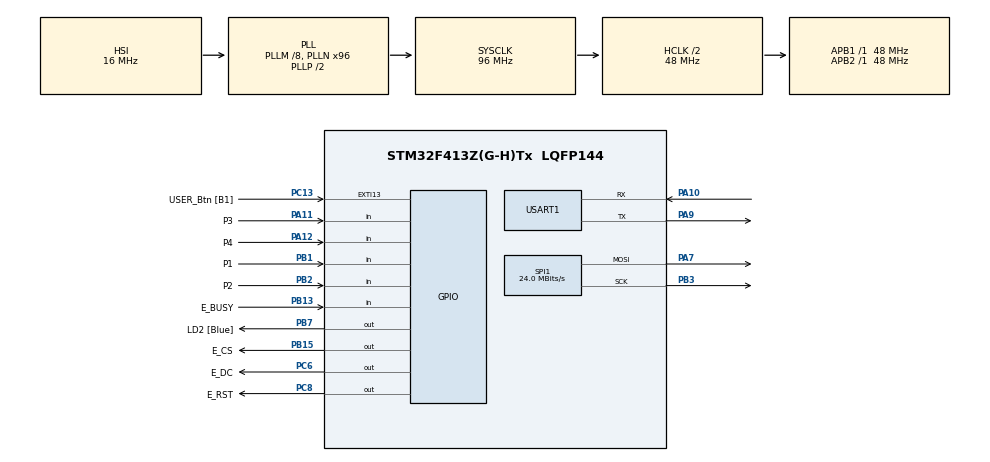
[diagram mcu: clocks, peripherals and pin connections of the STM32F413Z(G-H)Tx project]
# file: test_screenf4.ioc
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Mcu.Family=STM32F4
Mcu.Name=STM32F413Z(G-H)Tx
Mcu.Package=LQFP144
NVIC.PriorityGroup=NVIC_PRIORITYGROUP_4
PA10.Mode=Asynchronous
PA10.Signal=USART1_RX
PA11.GPIO_Label=P3
PA11.GPIO_PuPd=GPIO_PULLUP
PA11.Signal=GPIO_Input
PA12.GPIO_Label=P4
PA12.GPIO_PuPd=GPIO_PULLUP
PA12.Signal=GPIO_Input
PA13.Mode=Serial_Wire
PA13.Signal=SYS_JTMS-SWDIO
PA14.Mode=Serial_Wire
PA14.Signal=SYS_JTCK-SWCLK
PA7.Mode=TX_Only_Simplex_Unidirect_Master
PA7.Signal=SPI1_MOSI
PA9.Mode=Asynchronous
PA9.Signal=USART1_TX
PB1.GPIO_Label=P1
PB1.GPIO_PuPd=GPIO_PULLUP
PB1.Signal=GPIO_Input
PB13.GPIO_Label=E_BUSY
PB13.GPIO_PuPd=GPIO_PULLUP
PB13.Signal=GPIO_Input
PB15.GPIO_Label=E_CS
PB15.Signal=GPIO_Output
PB2.GPIO_Label=P2
PB2.GPIO_PuPd=GPIO_PULLUP
PB2.Signal=GPIO_Input
PB3.Mode=TX_Only_Simplex_Unidirect_Master
PB3.Signal=SPI1_SCK
PB7.GPIO_Label=LD2 [Blue]
PB7.Signal=GPIO_Output
PC13.GPIO_Label=USER_Btn [B1]
PC13.Signal=GPXTI13
PC14-OSC32_IN.Mode=LSE-External-Oscillator
PC14-OSC32_IN.Signal=RCC_OSC32_IN
PC15-OSC32_OUT.Mode=LSE-External-Oscillator
PC15-OSC32_OUT.Signal=RCC_OSC32_OUT
PC6.GPIO_Label=E_DC
PC6.Signal=GPIO_Output
PC8.GPIO_Label=E_RST
PC8.Signal=GPIO_Output
PH0\ -\ OSC_IN.Mode=HSE-External-Oscillator
PH0\ -\ OSC_IN.Signal=RCC_OSC_IN
PH1\ -\ OSC_OUT.Mode=HSE-External-Oscillator
PH1\ -\ OSC_OUT.Signal=RCC_OSC_OUT
ProjectManager.HeapSize=0x2000
ProjectManager.StackSize=0x400
ProjectManager.TargetToolchain=STM32CubeIDE
RCC.48MHZClocksFreq_Value=24000000
RCC.AHBCLKDivider=RCC_SYSCLK_DIV2
RCC.AHBFreq_Value=48000000
RCC.APB1Freq_Value=48000000
RCC.APB1TimFreq_Value=48000000
RCC.APB2Freq_Value=48000000
RCC.APB2TimFreq_Value=48000000
RCC.CortexFreq_Value=48000000
RCC.HCLKFreq_Value=48000000
RCC.HSE_VALUE=8000000
RCC.HSI_VALUE=16000000
RCC.PLLM=8
RCC.PLLMUL=RCC_PLL_MUL9
RCC.PLLN=96
RCC.PLLQ=8
RCC.PRESCALERUSB=RCC_USBCLKSOURCE_PLL_DIV1_5
RCC.SYSCLKFreq_VALUE=96000000
RCC.SYSCLKSource=RCC_SYSCLKSOURCE_PLLCLK
RCC.SYSCLKSourceVirtual=RCC_SYSCLKSOURCE_PLLCLK
RCC.USBFreq_Value=24000000
RCC.VCOOutputFreq_Value=192000000
SPI1.BaudRatePrescaler=SPI_BAUDRATEPRESCALER_2
SPI1.CalculateBaudRate=24.0 MBits/s
SPI1.Direction=SPI_DIRECTION_2LINES
SPI1.Mode=SPI_MODE_MASTER
SPI1.VirtualType=VM_MASTER
USART1.VirtualMode=VM_ASYNC
board=NUCLEO-F413ZH

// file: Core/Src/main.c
/* USER CODE BEGIN Header */
/**
  ******************************************************************************
  * @file           : main.c
  * @brief          : Main program body
  ******************************************************************************
  * @attention
  *
  * <h2><center>&copy; Copyright (c) 2020 STMicroelectronics.
  * All rights reserved.</center></h2>
  *
  * This software component is licensed by ST under BSD 3-Clause license,
  * the "License"; You may not use this file except in compliance with the
  * License. You may obtain a copy of the License at:
  *                        opensource.org/licenses/BSD-3-Clause
  *
  ******************************************************************************
  */
/* USER CODE END Header */

#include "main.h"
#include "epd2in7.h"
#include "epdif.h"
#include "epdpaint.h"
#include "imagedata.h"
//#include "tupian.h"
#include <stdlib.h>
#include <stdio.h>
/* USER CODE BEGIN Includes */
const unsigned char qie[] = {
		1,1,1,1,1,1,1,1,1,1,1,1,1,1,1,1,1,1,1,1,1,1,1,1,1,1,1,1,1,1,1,1,1,1,1,1,1,1,1,1,1,1,1,1,1,1,1,1,1,1,1,1,1,1,1,1,1,1,1,1,1,1,1,1,1,1,1,1,1,1,1,1,1,1,1,1,1,1,1,1,1,1,1,1,1,1,1,1,1,1,1,1,1,1,1,1,1,1,1,1,1,1,1,1,1,1,1,1,1,1,1,1,1,1,1,1,1,1,1,1,1,1,1,1,1,1,1,1,
		1,1,1,1,1,1,1,1,1,1,1,1,1,1,1,1,1,1,1,1,1,1,1,1,1,1,1,1,1,1,1,1,1,1,1,1,1,1,1,1,1,1,1,1,1,1,1,1,1,1,1,1,1,1,1,1,1,1,1,1,1,1,1,1,1,1,1,1,1,1,1,1,1,1,1,1,1,1,1,1,1,1,1,1,1,1,1,1,1,1,1,1,1,1,1,1,1,1,1,1,1,1,1,1,1,1,1,1,1,1,1,1,1,1,1,1,1,1,1,1,1,1,1,1,1,1,1,1,
		1,1,1,1,1,1,1,1,1,1,1,1,1,1,1,1,1,1,1,1,1,1,1,1,1,1,1,1,1,1,1,1,1,1,1,1,1,1,1,1,1,1,1,1,1,1,1,1,1,1,1,1,1,1,1,1,1,1,1,1,1,1,1,1,1,1,1,1,1,1,1,1,1,1,1,1,1,1,1,1,1,1,1,1,1,1,1,1,1,1,1,1,1,1,1,1,1,1,1,1,1,1,1,1,1,1,1,1,1,1,1,1,1,1,1,1,1,1,1,1,1,1,1,1,1,1,1,1,
		1,1,1,1,1,1,1,1,1,1,1,1,1,1,1,1,1,1,1,1,1,1,1,0,0,0,0,0,0,0,0,0,0,0,0,0,0,0,0,0,0,0,1,1,0,0,1,1,1,1,1,1,1,1,1,1,1,1,1,1,1,1,1,1,1,1,1,1,1,1,1,1,1,1,1,1,1,1,1,1,1,1,1,1,1,1,1,1,1,1,1,1,1,1,1,1,1,1,1,1,1,1,1,1,1,1,1,1,1,1,1,1,1,1,1,1,1,1,1,1,1,1,1,1,1,1,1,1,
		1,1,1,1,1,1,1,1,1,1,1,1,1,1,1,1,1,1,1,1,1,1,1,1,1,1,1,1,1,1,1,1,1,1,1,1,1,1,1,1,1,1,1,1,0,0,1,1,1,1,1,1,1,1,1,1,1,1,1,1,1,1,1,1,1,1,1,1,1,0,0,0,0,0,0,0,0,0,0,0,0,0,0,0,0,0,0,0,0,0,0,0,0,0,0,0,0,0,0,0,0,0,0,0,0,0,0,0,0,1,1,1,1,1,1,1,1,1,1,1,1,1,1,1,1,1,1,1,
		1,1,1,1,1,1,1,1,1,1,1,1,1,1,1,1,1,1,1,1,1,1,1,1,1,1,1,1,1,1,1,1,1,1,1,1,1,1,1,1,1,1,1,1,1,1,1,1,1,1,1,1,1,1,1,1,1,1,1,1,1,1,1,1,1,1,1,1,1,1,1,1,1,1,1,1,1,1,1,1,1,1,1,1,1,0,0,1,1,1,1,1,1,1,0,0,0,0,0,0,0,0,0,0,0,0,0,0,0,0,0,0,0,0,0,0,0,0,0,0,0,0,0,0,0,0,0,0,
		1,1,1,1,1,1,1,1,1,1,1,1,1,1,1,1,1,1,1,1,1,1,1,1,1,1,1,1,1,1,1,1,1,1,1,1,1,1,1,1,1,1,1,1,1,1,1,1,1,1,1,1,1,1,1,1,1,1,1,1,1,1,1,1,1,1,1,1,1,1,1,1,1,1,1,1,1,1,1,1,1,1,1,1,1,1,1,1,1,1,1,1,1,1,1,1,1,1,1,1,1,1,1,1,1,1,1,1,1,1,1,1,1,1,1,1,1,1,1,1,1,1,1,1,1,1,1,1,
		1,1,1,1,1,1,1,1,1,1,1,1,1,1,1,1,1,1,1,1,1,1,1,1,1,1,1,1,1,1,1,1,1,1,1,1,1,1,1,1,1,1,1,1,1,1,1,1,1,1,1,1,1,1,1,1,1,1,1,1,1,1,1,1,1,1,1,1,1,1,1,1,1,1,1,1,1,1,1,1,1,1,1,1,1,1,1,1,1,1,1,1,1,1,1,1,1,1,1,1,1,1,1,1,1,1,1,1,1,1,1,1,1,1,1,1,1,1,1,1,1,1,1,1,1,1,1,1,
		1,1,1,1,1,1,1,1,1,1,1,1,1,1,1,1,1,1,1,1,1,1,1,1,1,1,1,1,1,1,1,1,1,1,1,1,1,1,1,1,1,1,1,1,1,1,1,1,1,1,1,1,1,1,1,1,1,1,1,1,1,1,1,1,1,1,1,1,1,1,1,1,1,1,1,1,1,1,1,1,1,1,1,1,1,1,1,1,1,1,1,1,1,1,1,1,1,1,1,1,1,1,1,1,1,1,1,1,1,1,1,1,1,1,1,1,1,1,1,1,1,1,1,1,1,1,1,1,
		1,1,1,1,1,1,1,1,1,1,1,1,1,1,1,0,0,0,0,0,0,0,0,0,0,0,0,0,0,0,0,0,0,0,0,0,0,0,0,1,1,1,1,1,1,1,1,1,1,1,1,1,1,1,1,1,1,1,1,1,1,1,1,1,1,1,1,1,1,1,1,1,1,1,1,1,1,1,1,1,1,1,1,1,1,1,1,1,1,1,1,1,1,1,1,1,1,1,1,1,1,1,1,1,1,1,1,1,1,1,1,1,1,1,1,1,1,1,1,1,1,1,1,1,1,1,1,1,
		1,1,1,1,1,1,1,1,1,1,1,1,1,1,1,1,1,1,1,1,1,1,1,1,1,1,1,1,1,1,1,1,0,0,0,0,0,0,1,0,0,0,0,1,1,1,1,1,1,1,1,1,1,1,1,1,1,1,1,1,1,1,1,1,1,1,1,1,1,1,1,1,1,1,1,1,1,1,1,1,1,1,1,1,1,1,1,1,1,1,0,0,0,0,0,0,0,0,0,0,0,0,1,1,1,1,1,1,1,1,1,1,1,1,1,1,1,1,1,1,1,1,1,1,1,1,1,1,
		1,1,1,1,1,1,1,1,1,1,1,1,1,0,1,1,1,1,1,1,1,1,1,1,1,1,1,1,1,1,1,1,1,1,1,1,1,1,1,1,1,1,1,1,1,1,1,1,1,1,1,1,1,1,1,1,1,1,1,1,1,1,1,1,1,1,1,1,1,1,1,1,1,1,1,1,1,1,1,1,1,1,1,1,1,1,1,1,1,1,0,0,0,0,0,0,0,0,0,0,0,0,0,0,0,0,0,0,0,0,0,0,0,0,0,0,0,0,0,0,0,0,0,0,0,0,0,0,
		1,1,1,1,1,1,1,1,1,1,1,1,0,0,0,0,0,0,0,0,0,0,0,0,0,1,1,1,1,1,1,1,1,1,1,1,1,1,1,1,1,1,1,1,1,1,1,1,1,1,1,1,1,1,1,1,1,1,1,1,1,1,1,1,1,1,1,1,1,1,1,1,1,1,1,1,1,1,1,1,1,1,1,1,1,1,1,1,1,1,1,1,1,1,1,1,1,1,1,1,1,1,1,1,1,1,1,1,1,0,0,0,0,0,0,0,0,0,0,0,0,0,0,0,0,0,0,0,
		1,1,1,1,1,1,1,1,1,1,1,1,1,0,0,0,0,0,0,0,0,0,0,0,0,0,0,0,0,0,0,0,0,0,0,0,0,1,1,1,1,1,1,1,1,1,1,1,1,1,1,1,1,1,1,1,1,1,1,1,1,1,1,1,1,1,1,1,1,1,1,1,1,1,1,1,1,1,1,1,1,1,1,1,1,1,1,1,1,1,1,1,1,1,1,1,1,1,1,1,1,1,1,1,1,1,1,1,1,1,1,1,1,1,1,1,1,1,1,1,1,1,1,1,1,1,1,1,
		1,1,1,1,1,1,1,1,1,1,1,1,1,1,1,1,1,1,1,1,1,1,1,1,1,1,1,1,1,1,1,1,1,1,1,1,1,1,1,1,1,1,1,1,1,1,1,1,1,1,1,1,1,1,1,1,1,1,1,1,1,1,1,1,1,1,1,1,1,1,1,1,1,1,1,1,1,1,1,1,1,1,1,1,1,1,1,1,1,1,1,1,0,0,0,0,0,0,0,0,0,0,0,0,0,0,0,0,0,0,0,0,0,0,0,0,0,0,0,0,0,0,0,0,0,0,0,0,
		1,1,1,1,1,1,1,1,1,1,1,1,1,1,1,1,1,1,1,1,1,1,1,1,1,1,1,1,1,1,1,1,1,1,1,1,1,1,1,1,1,1,1,1,1,1,1,1,1,1,1,1,1,1,1,1,1,1,1,1,1,1,1,1,1,1,1,1,1,1,1,1,1,1,1,1,1,1,1,1,1,1,1,1,1,1,1,1,1,1,1,1,1,1,1,1,0,0,0,0,0,0,0,0,0,0,0,0,0,0,0,0,0,0,0,0,0,0,0,0,0,0,0,0,0,0,0,0,
		1,1,1,1,1,1,1,1,1,1,1,1,1,1,1,1,1,1,1,1,1,1,1,1,1,1,1,1,1,1,1,1,1,1,1,1,1,1,1,1,1,1,1,1,1,1,1,1,1,1,1,1,1,1,1,1,1,1,1,1,1,1,1,1,1,1,1,1,1,1,1,1,1,1,1,1,1,1,1,1,1,1,1,1,1,1,1,1,1,1,1,1,1,1,1,1,1,1,1,1,1,1,1,1,1,1,1,1,1,1,1,1,1,1,1,1,1,1,1,1,1,1,1,1,1,1,1,1,
		1,1,1,1,1,1,1,1,1,1,1,1,1,1,1,1,1,1,1,1,1,1,1,1,1,1,1,1,1,1,1,1,1,1,1,1,1,1,1,1,1,1,1,1,1,1,1,1,1,1,1,1,1,1,1,1,1,1,1,1,1,1,1,1,1,1,1,1,1,1,1,1,1,1,1,1,1,1,1,1,1,1,1,1,1,1,1,1,1,1,1,1,1,1,1,1,1,1,1,1,1,1,1,1,1,1,1,1,1,1,1,1,1,1,1,1,1,1,1,1,1,1,1,1,1,1,1,1,
		1,1,1,1,1,1,1,1,1,1,1,1,1,1,1,1,1,1,1,1,1,1,1,1,1,1,1,1,1,1,1,1,1,1,1,1,1,1,1,1,1,1,1,1,1,1,1,1,1,1,1,1,1,1,1,1,1,1,1,1,1,1,1,1,1,1,1,1,1,1,1,1,1,1,1,1,1,1,1,1,1,1,1,1,1,1,1,1,1,1,1,1,1,1,1,1,1,1,1,1,1,1,1,1,1,1,1,1,1,1,1,1,1,1,1,1,1,1,1,1,1,1,1,1,1,1,1,1,
		1,1,1,1,1,1,1,1,1,1,1,1,1,1,1,1,1,1,1,1,1,1,1,1,1,1,1,1,1,1,1,1,1,1,1,1,1,1,1,1,1,1,1,1,1,1,1,1,1,1,1,1,1,1,1,1,1,1,1,1,1,1,1,1,1,1,1,1,1,1,1,1,1,1,1,1,1,1,1,1,1,1,1,1,1,1,1,1,1,1,1,1,1,1,1,1,1,1,1,1,1,1,1,1,1,1,1,1,1,1,1,1,1,1,1,1,1,1,1,1,1,1,1,1,1,1,1,1,
		1,1,1,1,1,1,1,1,1,1,1,1,1,1,1,1,1,1,1,1,1,1,1,1,1,1,1,1,1,1,1,1,1,1,1,1,1,1,1,1,1,1,1,1,1,1,1,1,1,1,1,1,1,1,1,1,1,1,1,1,1,1,1,1,1,1,1,1,1,1,1,1,1,1,1,1,1,1,1,1,1,1,1,1,1,1,1,1,1,1,1,1,1,1,1,1,1,1,1,1,1,1,1,1,1,1,1,1,1,1,1,1,1,1,1,1,1,1,1,1,1,1,1,1,1,1,1,1,
		1,1,1,1,1,1,1,1,1,1,1,1,1,1,1,1,1,1,1,1,1,1,1,1,1,1,1,1,1,1,1,1,1,1,1,1,1,1,1,1,1,1,1,1,1,1,1,1,1,1,1,1,1,1,1,1,1,1,1,1,1,1,1,1,1,1,1,1,1,1,1,1,1,1,1,1,1,1,1,1,1,1,1,1,1,1,1,1,1,1,1,1,1,1,1,1,1,1,1,1,1,1,1,1,1,1,1,1,1,1,1,1,1,1,1,1,1,1,1,1,1,1,1,1,1,1,1,1,
		1,1,1,1,1,1,1,1,1,1,1,1,1,1,1,1,1,1,1,1,1,1,1,1,1,1,1,1,1,1,1,1,1,1,1,1,1,1,1,1,1,1,1,1,1,1,1,1,1,1,1,1,1,1,1,1,1,1,1,1,1,1,1,1,1,1,1,1,1,1,1,1,1,1,1,1,1,1,1,1,1,1,1,1,1,1,1,1,1,1,1,1,1,1,1,1,1,1,1,1,1,1,1,1,1,1,1,1,1,1,1,1,1,1,1,1,1,1,1,1,1,1,1,1,1,1,1,1,
		1,1,1,1,1,1,1,1,1,1,1,1,1,1,1,1,1,1,1,1,1,1,1,1,1,1,1,1,1,1,1,1,1,1,1,1,1,1,1,1,1,1,1,1,1,1,1,1,1,1,1,1,1,1,1,1,1,1,1,1,1,1,1,1,1,1,1,1,1,1,1,1,1,1,1,1,1,1,1,1,1,1,1,1,1,1,1,1,1,1,1,1,1,1,1,1,1,1,1,1,1,1,1,1,1,1,1,1,1,1,1,1,1,1,1,1,1,1,1,1,1,1,1,1,1,1,1,1,
		1,1,1,1,1,1,1,1,1,1,1,1,1,1,1,1,1,1,1,1,1,1,1,1,1,1,1,1,1,1,1,1,1,1,1,1,1,1,1,1,1,1,1,1,1,1,1,1,1,1,1,1,1,1,1,1,1,1,1,1,1,1,1,1,1,1,1,1,1,1,1,1,1,1,1,1,1,1,1,1,1,1,1,1,1,1,1,1,1,1,1,1,1,1,1,1,1,1,1,1,1,1,1,1,1,1,1,1,1,1,1,1,1,1,1,1,1,1,1,1,1,1,1,1,1,1,1,1,
		1,1,1,1,1,1,1,1,1,1,1,1,1,1,1,1,1,1,1,1,1,1,1,1,1,1,1,1,1,1,1,1,1,1,1,1,1,1,1,1,1,1,1,1,1,1,1,1,1,1,1,1,1,1,1,1,1,1,1,1,1,1,1,1,1,1,1,1,1,1,1,1,1,1,1,1,1,1,1,1,1,1,1,1,1,1,1,1,1,1,1,1,1,1,1,1,1,1,1,1,1,1,1,1,1,1,1,1,1,1,1,1,1,1,1,1,1,1,1,1,1,1,1,1,1,1,1,1,
		1,1,1,1,1,1,1,1,1,1,1,1,1,1,1,1,1,1,1,1,1,1,1,1,1,1,1,1,1,1,1,1,1,1,1,1,1,1,1,1,1,1,1,1,1,1,1,1,1,1,1,1,1,1,1,1,1,1,1,1,1,1,1,1,1,1,1,1,1,1,1,1,1,1,1,1,1,1,1,1,1,1,1,1,1,1,1,1,1,1,1,1,1,1,1,1,1,1,1,1,1,1,1,1,1,1,1,1,1,1,1,1,1,1,1,1,1,1,1,1,1,1,1,1,1,1,1,1,
		0,0,0,0,1,0,0,1,1,1,1,1,1,1,1,1,1,1,1,1,1,1,1,1,1,1,1,1,1,1,1,1,1,1,1,1,1,1,1,1,1,1,1,1,1,1,1,1,1,1,1,1,1,1,1,1,1,1,1,1,1,1,1,1,1,1,1,1,1,1,1,1,1,1,1,1,1,1,1,1,1,1,1,1,1,1,1,1,1,1,1,1,1,1,1,1,1,1,1,1,1,1,1,1,1,1,1,1,1,1,1,1,1,1,1,1,1,1,1,1,1,1,1,1,1,1,1,1,
		0,1,1,1,1,1,1,1,1,1,1,1,1,1,1,1,1,1,1,1,1,1,1,1,1,1,1,1,1,1,1,1,1,1,1,1,1,1,1,1,1,1,1,1,1,1,1,1,1,1,1,1,1,1,1,1,1,1,1,1,1,1,1,1,1,1,1,1,1,1,1,1,1,1,1,1,1,1,1,1,1,1,1,1,1,1,1,1,1,1,1,1,1,1,1,1,1,1,1,1,1,1,1,1,1,1,1,1,1,1,1,1,1,1,1,1,1,1,1,1,1,1,1,1,1,1,1,1,
		1,1,1,1,1,1,1,1,1,1,1,1,1,1,1,1,1,1,1,1,1,1,1,1,1,1,1,1,1,1,1,1,1,1,1,1,1,1,1,1,1,1,1,1,1,1,1,1,1,1,1,1,1,1,1,1,1,1,1,1,1,1,1,1,1,1,1,1,1,1,1,1,1,1,1,1,1,1,1,1,1,1,1,1,1,1,1,1,1,1,1,1,1,1,1,1,1,1,1,1,1,1,1,1,1,1,1,1,1,1,1,1,1,1,1,1,1,1,1,1,1,1,1,1,1,1,1,1,
		1,1,1,1,1,1,1,1,1,1,1,1,1,1,1,1,1,1,1,1,1,1,1,1,1,1,1,1,1,1,1,1,1,1,1,1,1,1,1,1,1,1,1,1,1,1,1,1,1,1,1,1,1,1,1,1,1,1,1,1,1,1,1,1,1,1,1,1,1,1,1,1,1,1,1,1,1,1,1,1,1,1,1,1,1,1,1,1,1,1,1,1,1,1,1,1,1,1,1,1,1,1,1,1,1,1,1,1,1,1,1,1,1,1,1,1,1,1,1,1,1,1,1,1,1,1,1,1,
		1,1,1,1,1,1,1,1,1,1,1,1,1,1,1,1,1,1,1,1,1,1,1,1,1,1,1,1,1,1,1,1,1,1,1,1,1,1,1,1,1,1,1,1,1,1,1,1,1,1,1,1,1,1,1,1,1,1,1,1,1,1,1,1,1,1,1,1,1,1,1,1,1,1,1,1,1,1,1,1,1,1,1,1,1,1,1,1,1,1,1,1,1,1,1,1,1,1,1,1,1,1,1,1,1,1,1,1,1,1,1,1,1,1,1,1,1,1,1,1,1,1,1,1,1,1,1,1,
		1,1,1,1,1,1,1,1,1,1,1,1,1,1,1,1,1,1,1,1,1,1,1,1,1,1,1,1,1,1,1,1,1,1,1,1,1,1,1,1,1,1,1,1,1,1,1,1,1,1,1,1,1,1,1,1,1,1,1,1,1,1,1,1,1,1,1,1,1,1,1,1,1,1,1,1,1,1,1,1,1,1,1,1,1,1,1,1,1,1,1,1,1,1,1,1,1,1,1,1,1,1,1,1,1,1,1,1,1,1,1,1,1,1,1,1,1,1,1,1,1,1,1,1,1,1,1,1,
		1,1,1,1,1,1,1,1,1,1,1,1,1,1,1,1,1,1,1,1,1,1,1,1,1,1,1,1,1,1,1,1,1,1,1,1,1,1,1,1,1,1,1,1,1,1,1,1,1,1,1,1,1,1,1,1,1,1,1,1,1,1,1,1,1,1,1,1,1,1,1,1,1,1,1,1,1,1,1,1,1,1,1,1,1,1,1,1,1,1,1,1,1,1,1,1,1,1,1,1,1,1,1,1,1,1,1,1,1,1,1,1,1,1,1,1,1,1,1,1,1,1,1,1,1,1,1,1,
		1,1,1,1,1,1,1,1,1,1,1,1,1,1,1,1,1,1,1,1,1,1,1,1,1,1,1,1,1,1,1,1,1,1,1,1,1,1,1,1,1,1,1,1,1,1,1,1,1,1,1,1,1,1,1,1,1,1,1,1,1,1,1,1,1,1,1,1,1,1,1,1,1,1,1,1,1,1,1,1,1,1,1,1,1,1,1,1,1,1,1,1,1,1,1,1,1,1,1,1,1,1,1,1,1,1,1,1,1,1,1,1,1,1,1,1,1,1,1,1,1,1,1,1,1,1,1,1,
		1,1,1,1,1,1,1,1,1,1,1,1,1,1,1,1,1,1,1,1,1,1,1,1,1,1,1,1,1,1,1,1,1,1,1,1,1,1,1,1,1,1,1,1,1,1,1,1,1,1,1,1,1,1,1,1,1,1,1,1,1,1,1,1,1,1,1,1,1,1,1,1,1,1,1,1,1,1,1,1,1,1,1,1,1,1,1,1,1,1,1,1,1,1,1,1,1,1,1,1,1,1,1,1,1,1,1,1,1,1,1,1,1,1,1,1,1,1,1,1,1,1,1,1,1,1,1,1,
		1,1,1,1,1,1,1,1,1,1,1,1,1,1,1,1,1,1,1,1,1,1,1,1,1,1,1,1,1,1,1,1,1,1,1,1,1,1,1,1,1,1,1,1,1,1,1,1,1,1,1,1,1,1,1,1,1,1,1,1,1,1,1,1,1,1,1,1,1,1,1,1,1,1,1,1,1,1,1,1,1,1,1,1,1,1,1,1,1,1,1,1,1,1,1,1,1,1,1,1,1,1,1,1,1,1,1,1,1,1,1,1,1,1,1,1,1,1,1,1,1,1,1,1,1,1,1,1,
		1,1,1,1,1,1,1,1,1,1,1,1,1,1,1,1,1,1,1,1,1,1,1,1,1,1,1,1,1,1,1,1,1,1,1,1,1,1,1,1,1,1,1,1,1,1,1,1,1,1,1,1,1,1,1,1,1,1,1,1,1,1,1,1,1,1,1,1,1,1,1,1,1,1,1,1,1,1,1,1,1,1,1,1,1,1,1,1,1,1,1,1,1,1,1,1,1,1,1,1,1,1,1,1,1,1,1,1,1,1,1,1,1,1,1,1,1,1,1,1,1,1,1,1,1,1,1,1,
		1,1,1,1,1,1,1,1,1,1,1,1,1,1,1,1,1,1,1,1,1,1,1,1,1,1,1,1,1,1,1,1,1,1,1,1,1,1,1,1,1,1,1,1,1,1,1,1,1,1,1,1,1,1,1,1,1,1,1,1,1,1,1,1,1,1,1,1,1,1,1,1,1,1,1,1,1,1,1,1,1,1,1,1,1,1,1,1,1,1,1,1,1,1,1,1,1,1,1,1,1,1,1,1,1,1,1,1,1,1,1,1,1,1,1,1,1,1,1,1,1,1,1,1,1,1,1,1,
		1,1,1,1,1,1,1,1,1,1,1,1,1,1,1,1,1,1,1,1,1,1,1,1,1,1,1,1,1,1,1,1,1,1,1,1,1,1,1,1,1,1,1,1,1,1,1,1,1,1,1,1,1,1,1,1,1,1,1,1,1,1,1,1,1,1,1,1,1,1,1,1,0,1,1,1,1,1,1,1,1,1,1,1,1,1,1,1,1,1,1,1,1,1,1,1,1,1,1,1,1,1,1,1,1,1,1,1,1,1,1,1,1,1,1,1,1,1,1,1,1,1,1,1,1,1,1,1,
		1,1,1,1,1,1,1,1,1,1,1,1,1,1,1,1,1,1,1,1,1,1,1,1,1,1,1,1,1,1,1,1,1,1,1,1,1,1,1,1,1,1,1,1,1,1,1,1,1,1,1,1,1,1,1,1,1,1,1,1,1,1,1,0,1,1,1,0,0,0,0,0,0,0,0,0,1,1,1,1,1,1,1,1,1,1,1,1,1,1,1,1,1,1,1,1,1,1,1,1,1,1,1,1,1,1,1,1,1,1,1,1,1,1,1,1,1,1,1,1,1,1,1,1,1,1,1,1,
		1,1,1,1,1,1,1,1,1,1,1,1,1,1,1,1,1,1,1,1,1,1,1,1,1,1,1,1,1,1,1,1,1,1,1,1,1,1,1,1,1,1,1,1,1,1,1,1,1,1,1,1,1,1,1,1,1,1,1,1,0,0,0,0,0,0,0,0,0,0,0,0,0,0,0,0,0,0,1,1,1,1,1,1,1,1,1,1,1,1,1,1,1,1,1,1,1,1,1,1,1,1,1,1,1,1,1,1,1,1,1,1,1,1,1,1,1,1,1,1,1,1,1,1,1,1,1,1,
		1,1,1,1,1,1,1,1,1,1,1,1,1,1,1,0,0,0,0,0,0,0,1,1,1,1,1,1,1,1,1,1,1,1,1,1,1,1,1,1,1,1,1,1,1,1,1,1,1,1,1,1,1,1,1,0,0,0,0,0,0,0,0,0,0,0,0,0,0,0,0,0,0,0,0,0,0,0,0,0,1,1,1,1,1,1,1,1,1,1,1,1,1,1,1,1,1,1,1,1,1,1,1,1,1,1,1,1,1,1,1,1,1,1,1,1,1,1,1,1,1,1,1,1,1,1,1,1,
		1,1,1,1,1,1,1,1,1,1,1,1,1,1,0,0,1,1,1,1,1,1,1,1,1,1,1,1,1,1,1,1,1,1,1,1,1,1,1,1,1,1,1,1,1,1,1,1,1,1,0,0,0,0,0,0,0,0,0,0,0,0,0,0,0,0,0,0,0,0,0,0,0,0,0,0,0,0,0,0,0,0,1,1,1,1,1,1,1,1,1,1,1,1,1,1,1,1,1,1,1,1,1,1,1,1,0,0,0,0,0,0,0,0,0,0,0,0,0,0,0,0,0,0,0,0,0,0,
		1,1,1,1,1,1,1,1,1,1,1,1,1,1,0,0,1,1,1,1,1,1,1,1,1,1,1,1,1,1,1,1,1,1,1,1,1,1,1,1,1,1,1,1,1,1,1,1,0,0,0,0,0,0,0,0,0,0,0,0,0,0,0,0,0,0,0,0,0,0,0,0,0,0,0,0,0,0,0,0,0,0,1,1,1,1,1,1,1,1,1,1,1,1,1,1,1,1,1,1,1,1,1,1,1,1,1,1,1,1,1,1,1,1,1,1,1,1,1,1,1,1,1,1,1,1,0,0,
		1,1,1,1,1,1,1,1,1,1,1,1,1,1,1,0,1,1,1,1,1,1,1,1,1,1,1,1,1,1,1,1,1,1,1,1,1,1,1,1,1,1,1,1,1,1,0,0,0,0,0,0,0,0,0,0,0,0,0,0,0,0,0,0,0,0,0,0,0,0,0,0,0,0,0,0,0,0,0,0,0,0,0,1,1,1,1,1,1,1,1,1,1,1,1,1,1,1,1,1,1,1,1,1,1,1,1,1,1,1,1,1,1,1,1,1,1,1,1,1,1,1,1,1,1,1,1,1,
		1,1,1,1,1,1,1,1,1,1,1,1,1,1,1,1,1,1,1,1,1,1,1,1,1,1,1,1,1,1,1,1,1,1,1,1,1,1,1,1,1,1,1,1,0,0,0,0,0,0,0,0,0,0,0,0,0,0,0,0,0,0,0,0,0,0,0,0,0,0,0,0,0,0,0,0,0,0,0,0,0,0,0,1,1,1,1,1,1,1,1,1,1,1,1,1,1,1,1,1,1,1,1,1,1,1,1,1,1,1,1,1,1,1,1,1,1,1,1,1,1,1,1,1,1,1,1,1,
		1,1,1,1,1,1,1,1,1,1,1,1,1,1,1,1,1,1,1,1,1,1,1,1,1,1,1,1,1,1,1,1,1,1,1,1,1,1,1,1,1,1,1,1,0,0,0,0,0,0,0,0,0,0,0,0,0,0,0,0,0,0,0,0,0,0,0,0,0,0,0,0,0,0,0,0,0,0,0,0,0,0,0,0,1,1,1,1,1,1,1,1,1,1,1,1,1,1,1,1,1,1,1,1,1,1,1,1,1,1,1,1,1,1,1,1,1,1,1,1,1,1,1,1,1,1,1,1,
		1,1,1,1,1,1,1,1,1,1,1,1,1,1,1,1,1,1,1,1,1,1,1,1,1,1,1,1,1,1,1,1,1,1,1,1,1,1,1,1,1,1,1,0,0,0,0,0,0,0,0,0,0,0,0,0,0,0,0,0,0,0,0,0,0,0,0,0,0,0,0,0,0,0,0,0,0,0,0,0,0,0,0,0,0,1,1,1,1,1,1,1,1,1,1,1,1,1,1,1,1,1,1,1,1,1,1,1,1,1,1,1,1,1,1,1,1,1,1,1,1,1,1,1,1,1,1,1,
		1,1,1,1,1,1,1,1,1,1,1,1,1,1,1,1,1,1,1,1,1,1,1,1,1,1,1,1,1,1,1,1,1,1,1,1,1,1,1,1,1,1,0,0,0,0,0,0,0,0,0,0,0,0,0,0,0,0,0,0,0,0,0,0,0,0,0,0,0,0,0,0,0,0,0,0,0,0,0,0,0,0,0,0,0,1,1,1,1,1,1,1,1,1,1,1,1,1,1,1,1,1,1,1,1,1,1,1,1,1,1,1,1,1,1,1,1,1,1,1,1,1,1,1,1,1,1,1,
		1,1,1,1,1,1,1,1,1,1,1,1,1,1,1,1,1,1,1,1,1,1,1,1,1,1,1,1,1,1,1,1,1,1,1,1,1,1,1,1,0,0,0,0,0,0,0,0,0,0,0,0,0,0,0,0,0,0,0,0,0,0,0,0,0,0,0,0,0,0,0,0,0,0,0,0,0,0,0,0,0,0,0,0,0,0,1,1,1,1,1,1,1,1,1,1,1,1,1,1,1,1,1,1,1,1,1,1,1,1,1,1,1,1,1,1,1,1,1,1,1,1,1,1,1,1,1,1,
		1,1,1,1,1,1,1,1,1,1,1,1,1,1,1,1,1,1,1,1,1,1,1,1,1,1,1,1,1,1,1,1,1,1,1,1,1,1,1,1,0,0,0,0,0,0,0,0,0,0,0,0,0,0,0,0,0,0,0,0,0,0,0,0,0,0,0,0,0,0,0,0,0,0,0,0,0,0,0,0,0,0,0,0,0,0,0,0,1,1,1,1,1,1,1,1,1,1,1,1,1,1,1,1,1,1,1,1,1,1,1,1,1,1,1,1,1,1,1,1,1,1,1,1,1,1,1,1,
		1,1,1,1,1,1,1,1,1,1,1,1,1,1,1,1,1,1,1,1,1,1,1,1,1,1,1,1,1,1,1,1,1,1,1,1,1,1,1,0,0,0,0,0,0,0,0,0,0,0,0,0,0,0,0,0,0,0,0,0,0,0,0,0,0,0,0,0,0,0,0,0,0,0,0,0,0,0,0,0,0,0,0,0,0,0,0,0,0,0,0,1,1,1,1,1,1,1,1,1,1,1,1,1,1,1,1,1,1,1,1,1,1,1,1,1,1,1,1,1,1,1,1,1,1,1,1,1,
		1,1,1,1,1,1,1,1,1,1,1,1,1,1,1,1,1,1,1,1,1,1,1,1,1,1,1,1,1,1,1,1,1,1,1,1,1,1,0,0,0,0,0,0,0,0,0,0,0,0,0,0,0,0,0,0,0,0,0,0,0,0,0,0,0,0,0,0,0,0,0,0,0,0,0,0,0,0,0,0,0,0,0,0,0,0,0,0,0,0,0,1,1,1,1,1,1,1,1,1,1,1,1,1,1,1,1,1,1,1,1,1,1,1,1,1,1,1,1,1,1,1,1,1,1,1,1,1,
		1,1,1,1,1,1,1,1,1,1,1,1,1,1,1,1,1,1,1,1,1,1,1,1,1,1,1,1,1,1,1,1,1,1,1,1,0,0,0,0,0,0,0,0,0,0,0,0,0,0,0,0,0,0,0,0,0,0,0,0,0,0,0,0,0,0,0,0,0,0,0,0,0,0,0,0,0,0,0,0,0,0,0,0,0,0,0,0,0,0,0,0,0,1,1,1,1,1,1,1,1,1,1,1,1,1,1,1,1,1,1,1,1,1,1,1,1,1,1,1,1,1,1,1,1,1,1,1,
		1,1,1,1,1,1,1,1,1,1,1,1,1,1,1,1,1,1,1,1,1,1,1,1,1,1,1,1,1,1,1,1,1,1,1,1,0,0,0,0,0,0,0,0,0,0,0,0,0,0,0,0,0,0,0,0,0,0,0,0,0,0,0,0,0,0,0,0,0,0,0,0,0,0,0,0,0,0,0,0,0,0,0,0,0,0,0,0,0,0,0,0,0,0,1,1,1,1,1,1,1,1,1,1,1,1,1,1,1,1,1,1,1,1,1,1,1,1,1,1,1,1,1,1,1,1,1,1,
		1,1,1,1,1,1,1,1,1,1,1,1,1,1,1,1,1,1,1,1,1,1,1,1,1,1,1,1,1,1,1,1,1,1,1,0,0,0,0,0,0,0,0,0,0,0,0,0,0,0,0,0,0,0,0,0,0,0,0,0,0,0,0,0,0,0,0,0,0,0,0,0,0,0,0,0,0,0,0,0,0,0,0,0,0,0,0,0,0,0,0,0,0,0,1,1,1,1,1,1,1,1,1,1,1,1,1,1,1,1,1,1,1,1,1,1,1,1,1,1,1,1,1,1,1,1,1,1,
		1,1,1,1,1,1,1,1,1,1,1,1,1,1,1,1,1,1,1,1,1,1,1,1,1,1,1,1,1,1,1,1,1,1,1,0,0,0,0,0,0,0,0,0,0,0,0,0,0,0,0,0,0,0,0,0,0,0,0,0,0,0,0,0,0,0,0,0,0,0,0,0,0,0,0,0,0,0,0,0,0,0,0,0,0,0,0,0,0,0,0,0,0,0,0,1,1,1,1,1,1,1,1,1,1,1,1,1,1,1,1,1,1,1,1,1,1,1,1,1,1,1,1,1,1,1,1,1,
		1,1,1,1,1,1,1,1,1,1,1,1,1,1,1,1,1,1,1,1,1,1,1,1,1,1,1,1,1,1,1,1,1,1,0,0,0,0,0,0,0,0,0,0,0,0,0,0,0,0,0,0,0,0,0,0,0,0,0,0,0,0,0,0,0,0,0,0,0,0,0,0,0,0,0,0,0,0,0,0,0,0,0,0,0,0,0,0,0,0,0,0,0,0,0,0,1,1,1,1,1,1,1,1,1,1,1,1,1,1,1,1,1,1,1,1,1,1,1,1,1,1,1,1,1,1,1,1,
		1,1,1,1,1,1,1,1,1,1,1,1,1,1,1,1,1,1,1,1,1,1,1,1,1,1,1,1,1,1,1,1,1,1,0,0,0,0,0,0,0,0,0,0,0,0,0,0,0,0,0,0,0,0,0,0,0,0,0,0,0,0,0,0,0,0,0,0,0,0,0,0,0,0,0,0,0,0,0,0,0,0,0,0,0,0,0,0,0,0,0,0,0,0,0,0,1,1,1,1,1,1,1,1,1,1,1,1,1,1,1,1,1,1,1,1,1,1,1,1,1,1,1,1,1,1,1,1,
		1,1,1,1,1,1,1,1,1,1,1,1,1,1,1,1,1,1,1,1,1,1,1,1,1,1,1,1,1,1,1,1,1,1,0,0,0,0,0,0,0,0,0,0,0,0,0,0,0,0,0,0,0,0,0,0,0,0,0,0,0,0,0,0,0,0,0,0,0,0,0,0,0,0,0,0,0,0,0,0,0,0,0,0,0,0,0,0,0,0,0,0,0,0,0,0,0,1,1,1,1,1,1,1,1,1,1,1,1,1,1,1,1,1,1,1,1,1,1,1,1,1,1,1,1,1,1,1,
		1,1,1,1,1,1,1,1,1,1,1,1,1,1,1,1,1,1,1,1,1,1,1,1,1,1,1,1,1,1,1,1,1,1,0,0,0,0,0,0,0,0,0,0,0,0,0,0,0,0,0,0,0,0,0,0,0,0,0,0,0,0,0,0,0,0,0,0,0,0,0,0,0,0,0,0,0,0,0,0,0,0,0,0,0,0,0,0,0,0,0,0,0,0,0,0,0,0,1,1,1,1,1,1,1,1,1,1,1,1,1,1,1,1,1,1,1,1,1,1,1,1,1,1,1,1,1,1,
		1,1,1,1,1,1,1,1,1,1,1,1,1,1,1,1,1,1,1,1,1,1,1,1,1,1,1,1,1,1,1,1,1,0,0,0,0,0,0,0,0,0,0,0,0,0,0,0,0,0,0,0,0,0,0,0,0,0,0,0,0,0,0,0,0,0,0,0,0,0,0,0,0,0,0,0,0,0,0,0,0,0,0,0,0,0,0,0,0,0,0,0,0,0,0,0,0,0,1,1,1,1,1,1,1,1,1,1,1,1,1,1,1,1,1,1,1,1,1,1,1,1,1,1,1,1,1,1,
		1,1,1,1,1,1,1,1,1,1,1,1,1,1,1,1,1,1,1,1,1,1,1,1,1,1,1,1,1,1,1,1,1,0,0,0,0,0,0,0,0,0,0,0,0,0,0,0,0,0,0,0,0,0,0,0,0,0,0,0,0,0,0,0,0,0,0,0,0,0,0,0,0,0,0,0,0,1,1,1,0,0,0,0,0,0,0,0,0,0,0,0,0,0,0,0,0,0,1,1,1,1,1,1,1,1,1,1,1,1,1,1,1,1,1,1,1,1,1,1,1,1,1,1,1,1,1,1,
		1,1,1,1,1,1,1,1,1,1,1,1,1,1,1,1,1,1,1,1,1,1,1,1,1,1,1,1,1,1,1,1,1,0,0,0,0,0,0,0,0,0,0,0,0,0,0,0,0,0,0,0,0,0,0,0,0,0,0,0,0,0,0,0,0,0,0,0,0,0,1,1,1,1,1,1,1,1,1,1,1,1,1,0,0,0,0,0,0,0,0,0,0,0,0,0,0,0,1,1,1,1,1,1,1,1,1,1,1,1,1,1,1,1,1,1,1,1,1,1,1,1,1,1,1,1,1,1,
		1,1,1,1,1,1,1,1,1,1,1,1,1,1,1,1,1,1,1,1,1,1,1,1,1,1,1,1,1,1,1,1,1,0,0,0,0,0,0,0,0,0,0,1,1,1,1,1,1,1,1,0,0,0,0,0,0,0,0,0,0,0,0,0,0,0,0,1,1,1,1,1,1,1,1,1,1,1,1,1,1,1,1,1,1,0,0,0,0,0,0,0,0,0,0,0,0,0,0,1,1,1,1,1,1,1,1,1,1,1,1,1,1,1,1,1,1,1,1,1,1,1,1,1,1,1,1,1,
		1,1,1,1,1,1,1,1,1,1,1,1,1,1,1,1,1,1,1,1,1,1,1,1,1,1,1,1,1,1,1,1,0,0,0,0,0,0,0,0,0,1,1,1,1,1,1,1,1,1,1,1,1,1,1,1,1,0,0,0,0,0,0,0,1,1,1,1,1,1,1,1,1,1,1,1,1,1,1,1,1,1,1,1,1,0,0,0,0,0,0,0,0,0,0,0,0,0,0,1,1,1,1,1,1,1,1,1,1,1,1,1,1,1,1,1,1,1,1,1,1,1,1,1,1,1,1,1,
		1,1,1,1,1,1,1,1,1,1,1,1,1,1,1,1,1,1,1,1,1,1,1,1,1,1,1,1,1,1,1,1,0,0,0,0,0,0,0,0,1,1,1,1,1,1,1,1,1,1,1,1,1,1,1,1,1,1,1,0,0,0,0,1,1,1,1,1,1,1,1,1,1,1,1,1,1,1,1,1,1,1,1,1,1,0,0,0,0,0,0,0,0,0,0,0,0,0,0,1,1,1,1,1,1,1,1,1,1,1,1,1,1,1,1,1,1,1,1,1,1,1,1,1,1,1,1,1,
		1,1,1,1,1,1,1,1,1,1,1,1,1,1,1,1,1,1,1,1,1,1,1,1,1,1,1,1,1,1,1,1,0,0,0,0,0,0,0,1,1,1,1,1,1,1,1,1,1,1,1,1,1,1,1,1,1,1,1,1,0,1,1,1,1,1,1,1,1,1,1,1,1,1,1,1,1,1,1,1,1,1,1,1,1,0,0,1,0,0,0,0,0,0,0,0,0,0,0,1,1,1,1,1,1,1,1,1,1,1,1,1,1,1,1,1,1,1,1,1,1,1,1,1,1,1,1,1,
		1,1,1,1,1,1,1,1,1,1,1,1,1,1,1,1,1,1,1,1,1,1,1,1,1,1,1,1,1,1,1,1,0,0,0,0,0,0,1,1,1,1,1,1,1,1,1,1,1,1,1,1,1,1,1,1,1,1,1,1,1,1,1,1,1,1,1,1,1,1,1,1,1,1,1,1,1,1,1,1,1,1,1,1,1,1,1,1,1,0,0,0,0,0,0,0,0,0,0,1,1,1,1,1,1,1,1,1,1,1,1,1,1,1,1,1,1,1,1,1,1,1,1,1,1,1,1,1,
		1,1,1,1,1,1,1,1,1,1,1,1,1,1,1,1,1,1,1,1,1,1,1,1,1,1,1,1,1,1,1,1,0,0,0,0,0,0,1,1,1,0,0,0,0,0,0,0,1,1,1,1,1,1,1,1,1,1,1,1,1,1,1,1,1,1,1,1,1,1,1,1,1,1,1,1,1,1,1,0,0,1,1,1,1,1,1,1,0,0,0,0,0,1,0,0,1,1,1,1,1,1,1,1,1,0,1,1,1,1,1,1,1,1,1,1,1,1,1,1,1,1,1,1,1,1,1,1,
		1,1,1,1,1,1,1,1,1,1,1,1,1,1,1,1,1,1,1,1,1,1,1,1,1,1,1,1,1,1,1,1,0,0,0,0,0,1,0,1,1,0,0,0,0,0,0,0,1,1,1,1,1,1,1,1,1,1,1,1,1,1,1,1,1,1,1,1,1,1,1,1,1,1,1,1,0,0,0,0,0,0,1,1,1,1,1,1,1,1,0,0,1,1,0,0,0,1,1,1,1,1,1,0,0,0,0,0,1,1,1,1,1,1,1,1,1,1,1,1,1,1,1,1,1,1,1,1,
		1,1,1,1,1,1,1,1,1,1,1,1,1,1,1,1,1,1,1,1,1,1,1,1,1,1,1,1,1,1,1,1,0,0,0,0,0,0,0,1,0,0,0,0,0,0,0,0,1,1,1,1,1,1,1,1,1,1,1,1,0,0,0,1,1,1,1,1,1,1,1,1,1,1,1,1,1,1,1,1,1,1,1,1,1,1,1,1,1,1,0,0,0,0,0,0,0,0,0,1,1,1,0,0,0,0,0,0,1,1,1,1,1,1,1,1,1,1,1,1,1,1,1,1,1,1,1,1,
		1,1,1,1,1,1,1,1,1,1,1,1,1,1,1,1,1,1,1,1,1,1,1,1,1,1,1,1,1,1,1,1,0,0,0,0,0,0,0,0,0,1,1,0,0,0,0,0,0,1,1,1,1,1,1,1,1,1,0,0,0,0,0,0,0,0,1,1,1,1,1,1,1,1,1,1,1,1,1,1,1,1,1,1,1,1,1,1,1,1,0,0,0,0,0,0,0,0,0,0,1,1,0,0,0,0,1,1,1,1,1,1,1,1,1,1,1,1,1,1,1,1,1,1,1,1,1,1,
		1,1,1,1,1,1,1,1,1,1,1,1,1,1,1,1,1,1,1,1,1,1,1,1,1,1,1,1,1,1,1,0,0,0,0,0,0,0,0,0,0,1,0,0,1,1,1,1,1,1,1,1,1,1,1,1,1,1,1,0,0,0,0,0,0,0,1,1,1,1,1,1,1,1,1,1,1,1,1,1,1,1,1,1,1,1,1,1,0,0,0,0,0,0,0,0,0,0,0,0,1,1,0,0,0,1,1,1,1,1,1,1,1,1,1,1,1,1,1,1,1,1,1,1,1,1,1,1,
		1,1,1,1,1,1,1,1,1,1,1,1,1,1,1,1,1,1,1,1,1,1,1,1,1,1,1,1,1,0,0,0,0,0,0,0,0,0,1,1,1,1,1,1,1,1,1,1,1,1,1,1,1,1,1,1,1,1,1,0,0,0,0,0,0,0,0,1,1,1,1,1,1,1,1,1,1,1,1,1,1,1,0,0,0,0,0,0,0,0,0,0,0,0,0,0,0,0,0,0,0,1,0,0,1,1,1,1,1,1,1,1,1,1,1,1,1,1,1,1,1,1,1,1,1,1,1,1,
		1,1,1,1,1,1,1,1,1,1,1,1,1,1,1,1,1,1,1,1,1,1,1,1,1,1,1,1,0,0,0,0,0,0,0,0,0,0,1,1,1,1,1,1,1,1,1,1,1,1,1,1,1,1,1,1,1,1,0,0,0,0,0,0,0,0,1,1,1,1,1,1,1,1,1,1,1,1,1,1,1,1,1,1,0,0,0,0,0,0,0,0,0,0,0,0,0,0,0,0,0,0,0,0,0,0,1,1,1,1,1,1,1,1,1,1,1,1,1,1,1,1,1,1,1,1,1,1,
		1,1,1,1,1,1,1,1,1,1,1,1,1,1,1,1,1,1,1,1,1,1,1,1,1,1,1,1,1,0,0,0,0,0,0,0,0,0,0,1,1,1,1,1,1,1,1,1,1,1,1,1,1,1,1,0,1,1,1,0,0,0,0,0,0,0,1,1,1,1,1,1,1,1,1,1,1,1,1,1,1,1,1,1,1,0,0,0,0,0,0,0,0,0,0,0,0,0,0,0,0,0,0,0,0,0,0,1,1,1,1,1,1,1,1,1,1,1,1,1,1,1,1,1,1,1,1,1,
		1,1,1,1,1,1,1,1,1,1,1,1,1,1,1,1,1,1,1,1,1,1,1,1,1,1,1,1,1,1,1,0,0,0,0,0,0,0,0,0,0,0,1,1,1,1,1,1,1,1,1,1,1,1,1,0,1,1,1,0,0,0,0,0,0,0,0,1,1,1,1,0,0,0,1,1,1,1,1,1,1,1,1,0,0,0,0,0,0,0,0,0,0,0,0,0,0,0,0,0,0,0,0,0,0,0,0,0,1,1,1,1,1,1,1,1,1,1,1,1,1,1,1,1,1,1,1,1,
		1,1,1,1,1,1,1,1,1,1,1,1,1,1,1,1,1,1,1,1,1,1,1,1,1,1,1,1,1,1,1,0,0,0,0,0,0,0,0,0,0,0,1,1,1,1,1,1,1,1,1,1,1,0,0,0,1,1,1,0,0,0,0,0,0,0,0,0,1,1,0,0,0,0,0,0,0,1,1,1,0,0,0,0,0,0,0,0,0,0,0,0,0,0,0,0,0,0,0,0,0,0,0,1,1,0,0,0,1,1,1,1,1,1,1,1,1,1,1,1,1,1,1,1,1,1,1,1,
		1,1,1,1,1,1,1,1,1,1,1,1,1,1,1,1,1,1,1,1,1,1,1,1,1,1,1,1,1,1,1,0,0,0,0,0,0,0,0,0,0,0,1,1,1,1,1,1,1,1,1,0,0,0,0,0,0,1,0,0,0,0,0,0,0,0,0,0,0,0,0,0,0,0,0,0,0,0,0,0,0,0,0,0,0,0,0,0,0,0,0,0,0,0,0,0,0,0,0,0,0,0,0,1,1,1,0,0,1,1,1,1,1,1,1,1,1,1,1,1,1,1,1,1,1,1,1,1,
		1,1,1,1,1,1,1,1,1,1,1,1,1,1,1,1,1,1,1,1,1,1,1,1,1,1,1,1,1,1,0,0,0,0,0,0,0,0,0,0,0,0,0,0,0,0,0,0,0,0,0,0,0,0,0,0,0,1,0,0,0,0,0,0,0,0,0,0,0,0,0,0,0,0,0,0,0,0,0,0,0,0,0,0,0,0,0,0,0,0,0,0,0,0,0,0,0,0,0,0,0,0,0,0,1,1,0,0,1,1,1,1,1,1,1,1,1,1,1,1,1,1,1,1,1,1,1,1,
		1,1,1,1,1,1,1,1,1,1,1,1,1,1,1,1,1,1,1,1,1,1,1,1,1,1,1,1,1,1,0,0,0,0,0,0,0,0,0,0,0,0,0,0,0,0,0,0,0,0,0,0,0,0,0,0,0,1,0,0,0,0,0,0,0,0,0,0,0,0,0,0,0,0,0,0,0,0,0,0,0,0,0,0,0,0,0,0,0,0,0,0,0,0,0,0,0,0,0,0,0,0,0,0,0,1,0,0,1,1,1,1,1,1,1,1,1,1,1,1,1,1,1,1,1,1,1,1,
		1,1,1,1,1,1,1,1,1,1,1,1,1,1,1,1,1,1,1,1,1,1,1,1,1,1,1,1,1,1,0,0,0,0,0,0,0,0,0,0,0,0,0,0,0,0,0,0,0,0,0,0,0,0,0,0,1,0,0,0,0,0,0,0,0,0,0,0,0,0,0,0,0,0,0,0,0,0,0,0,0,0,0,0,0,0,0,0,0,0,0,0,0,0,0,0,0,0,0,0,0,0,0,0,0,1,0,0,1,1,1,1,1,1,1,1,1,1,1,1,1,1,1,1,1,1,1,1,
		0,0,0,1,1,1,1,1,1,1,1,1,1,1,1,1,1,1,1,1,1,1,1,1,1,1,1,1,1,1,0,0,0,0,0,0,0,0,0,0,0,0,0,0,0,0,0,0,0,0,0,0,0,0,0,1,1,0,0,0,0,0,0,0,0,0,0,0,0,0,0,0,0,0,0,0,0,0,0,0,0,0,0,0,0,0,0,0,0,0,0,0,0,0,0,0,0,0,0,0,0,0,0,0,0,0,0,0,1,1,1,1,1,1,1,1,1,1,1,1,1,1,1,1,1,1,1,1,
		0,1,1,1,1,1,1,1,1,1,1,1,1,1,1,1,1,1,1,1,1,1,1,1,1,1,1,1,1,1,0,0,0,0,0,0,0,0,0,0,0,0,0,0,0,0,0,0,0,0,0,0,0,0,1,1,0,0,0,0,0,0,0,0,0,0,0,0,0,0,0,0,1,0,0,0,0,0,0,0,0,0,0,0,0,0,0,0,0,0,0,0,0,0,0,0,0,0,0,0,0,0,0,0,0,0,0,0,1,1,1,1,1,1,1,1,1,1,1,1,1,1,1,1,1,1,1,1,
		0,1,1,1,1,1,1,1,1,1,1,1,1,1,1,1,1,1,1,1,1,1,1,1,1,1,1,1,1,1,0,0,0,0,0,0,0,0,0,0,0,0,0,0,0,0,0,0,0,0,0,0,0,1,1,1,0,0,0,0,0,0,0,0,0,0,0,0,0,0,0,0,1,1,1,1,0,0,0,0,0,0,0,0,0,0,0,0,0,0,0,0,0,0,0,0,0,0,0,0,0,0,0,0,0,0,0,0,1,1,1,1,1,1,1,1,1,1,1,1,1,1,1,1,1,1,1,1,
		0,1,1,1,1,1,1,1,1,1,1,1,1,1,1,1,1,1,1,1,1,1,1,1,1,1,1,1,1,1,0,0,0,0,0,0,0,0,0,0,0,0,0,0,0,0,0,0,0,0,0,1,1,1,1,0,0,0,0,0,0,0,0,0,0,0,0,0,0,0,0,0,0,1,1,1,1,1,1,0,0,0,0,0,0,0,0,0,0,0,0,0,0,0,0,0,0,0,0,0,0,0,0,0,0,0,0,1,1,1,1,1,1,1,1,1,1,1,1,1,1,1,1,1,1,1,1,1,
		0,1,1,1,1,1,1,1,1,1,1,1,1,1,1,1,1,1,1,1,1,1,1,1,1,1,1,1,1,1,0,0,0,0,0,0,0,0,0,0,0,0,0,0,0,0,0,0,0,0,1,1,1,1,0,0,0,0,0,0,0,0,0,0,0,0,0,0,0,0,0,0,0,1,1,1,1,1,1,0,0,0,0,0,0,0,0,0,0,0,0,0,0,0,0,0,0,0,0,0,0,0,0,0,0,0,0,1,1,1,1,1,1,1,1,1,1,1,1,1,1,1,1,1,1,1,1,1,
		0,1,1,1,1,1,1,1,1,1,1,1,1,1,1,1,1,1,1,1,1,1,1,1,1,1,1,1,1,1,1,0,0,0,0,0,0,0,0,0,0,0,0,0,0,0,1,1,1,1,1,1,1,1,0,0,0,0,0,0,0,0,0,0,0,0,0,0,0,0,0,0,0,1,1,1,1,1,1,0,0,0,0,0,0,0,0,0,0,0,0,0,0,0,0,0,0,0,0,0,0,0,0,0,0,0,0,1,1,1,1,1,1,1,1,1,1,1,1,1,1,1,1,1,1,1,1,1,
		0,1,1,1,1,1,1,1,1,1,1,1,1,1,1,1,1,1,1,1,1,1,1,1,1,1,1,1,1,1,1,0,0,0,0,0,0,0,0,0,0,0,0,0,0,0,0,1,1,1,1,1,1,1,0,0,0,0,0,0,0,0,0,0,0,0,0,0,0,0,0,0,0,1,1,1,1,1,1,1,0,0,0,0,0,0,0,0,0,0,0,0,0,0,0,0,0,0,0,0,0,0,0,0,0,0,1,1,1,1,1,1,1,1,1,1,1,1,1,1,1,1,1,1,1,1,1,1,
		0,1,1,1,1,1,1,1,1,1,1,1,1,1,1,1,1,1,1,1,1,1,1,1,1,1,1,1,1,1,1,1,0,0,0,0,0,0,0,0,0,0,0,0,0,0,0,1,1,1,1,1,1,1,0,0,0,0,0,0,0,0,0,0,0,0,1,1,0,0,0,1,1,1,1,1,1,1,1,1,1,0,0,0,0,0,0,0,0,0,0,0,0,0,0,0,0,0,0,0,0,0,0,0,0,0,1,1,1,1,1,1,1,1,1,1,1,1,1,1,1,1,1,1,1,1,1,1,
		0,0,1,1,1,1,1,1,1,1,1,1,1,1,1,1,1,1,1,1,1,1,1,1,1,1,1,1,1,1,1,1,0,0,0,0,0,0,0,0,0,0,0,0,0,0,0,1,1,1,1,1,1,1,1,0,0,0,1,0,0,0,0,0,1,1,1,1,1,1,1,1,1,1,1,1,1,1,1,1,1,1,1,0,0,0,0,0,0,0,0,0,0,0,0,0,0,0,0,0,0,0,0,0,0,1,1,1,1,1,1,1,1,1,1,1,1,1,1,1,1,1,1,1,1,1,1,1,
		0,0,1,1,1,1,1,1,1,1,1,1,1,1,1,1,1,1,1,1,1,1,1,1,1,1,1,1,1,1,1,1,0,0,0,0,0,0,0,0,0,0,0,0,0,0,1,1,1,1,1,1,1,1,1,1,1,1,1,1,1,0,1,1,1,1,1,1,1,1,1,1,1,1,1,1,1,1,1,1,1,1,1,1,1,1,1,1,1,1,0,0,0,0,0,0,0,0,0,0,0,0,0,0,1,1,1,1,1,1,1,1,1,1,1,1,1,1,1,1,1,1,1,1,1,1,1,1,
		0,0,1,1,1,1,1,1,1,1,1,1,1,1,1,1,1,1,1,1,1,1,1,1,1,1,1,1,1,1,1,1,0,0,0,0,0,0,0,0,0,0,0,0,0,0,1,1,1,1,1,1,0,0,0,0,1,1,1,1,1,1,1,1,1,1,1,1,1,1,1,0,0,0,0,0,1,1,1,1,1,1,1,1,1,1,1,1,1,1,0,0,0,0,0,0,0,0,0,0,1,1,1,1,1,1,1,1,1,1,1,1,1,1,1,1,1,1,1,1,1,1,1,1,1,1,1,1,
		0,1,1,1,1,1,1,1,1,1,1,1,1,1,1,1,1,1,1,1,1,1,1,1,1,1,1,1,1,1,1,1,1,0,0,0,0,0,0,0,0,0,0,0,0,1,1,1,1,1,1,0,0,0,0,0,1,1,1,1,1,1,1,1,1,1,1,1,1,1,1,0,0,0,0,0,1,1,1,1,1,1,1,1,1,1,1,1,1,1,1,1,1,0,0,0,0,0,0,0,1,1,1,1,1,1,1,1,1,1,1,1,1,1,1,1,1,1,1,1,1,1,1,1,1,1,1,1,
		0,1,1,1,1,1,1,1,1,1,1,1,1,1,1,1,1,1,1,1,1,1,1,1,1,1,1,1,1,1,1,1,1,0,0,0,0,0,0,0,0,0,0,0,0,1,1,1,1,1,0,0,0,0,0,0,0,1,1,1,1,1,1,1,1,1,1,1,1,0,0,0,0,0,0,0,1,1,1,1,1,1,1,1,1,1,1,1,1,1,1,1,1,0,0,0,0,0,0,0,1,1,1,1,1,1,1,1,1,1,1,1,1,1,1,1,1,1,1,1,1,1,1,1,1,1,1,1,
		0,1,1,1,1,1,1,1,1,1,1,1,1,1,1,1,1,1,1,1,1,1,1,1,1,1,1,1,1,1,1,1,1,1,0,0,0,0,0,0,0,0,0,0,1,1,1,1,1,1,0,0,0,0,0,0,0,0,1,1,1,1,1,1,1,1,1,0,0,0,0,0,0,0,0,0,1,1,1,1,1,1,1,1,1,1,1,1,1,1,1,1,1,0,0,0,0,0,0,1,1,1,1,1,1,1,1,1,1,1,1,1,1,1,1,1,1,1,1,1,1,1,1,1,1,1,1,1,
		0,1,1,1,1,1,1,1,1,1,1,1,1,1,1,1,1,1,1,1,1,1,1,1,1,1,1,1,1,1,1,1,1,1,0,0,0,0,0,0,0,1,0,1,1,1,1,1,1,1,0,0,0,0,0,0,0,0,0,0,0,1,1,1,1,1,0,0,0,0,0,0,0,0,0,0,1,1,1,1,1,1,1,1,1,1,1,1,1,1,1,1,1,0,0,0,0,0,0,1,1,1,1,1,1,1,1,1,1,1,1,1,1,1,1,1,1,1,1,1,1,1,1,1,1,1,1,1,
		0,1,1,1,1,1,1,1,1,1,1,1,1,1,1,1,1,1,1,1,1,1,1,1,1,1,1,1,1,1,1,1,1,1,1,0,0,0,0,0,0,1,0,1,1,1,1,1,1,1,1,1,0,0,0,0,0,0,0,0,0,0,0,0,0,0,0,0,0,0,0,0,0,0,0,0,1,1,1,1,1,1,1,1,1,1,1,1,1,1,1,1,1,1,0,0,0,0,0,1,1,1,1,1,1,1,1,1,1,1,1,1,1,1,1,1,1,1,1,1,1,1,1,1,1,1,1,1,
		0,1,1,1,1,1,1,1,1,1,1,1,1,1,1,1,1,1,1,1,1,1,1,1,1,1,1,1,1,1,1,1,1,1,1,0,0,0,0,0,0,0,0,1,1,1,1,1,1,1,1,1,0,0,0,0,0,0,0,1,1,1,1,1,1,1,1,1,1,1,1,1,1,1,1,1,1,1,1,1,1,1,1,1,1,1,1,1,1,1,1,1,1,1,0,0,0,0,1,1,1,1,1,1,0,0,0,0,0,0,0,0,0,0,0,0,0,0,0,0,0,0,0,0,0,0,0,0,
		0,1,1,1,1,1,1,1,1,1,1,1,1,1,1,1,1,1,1,1,1,1,1,1,1,1,1,1,1,1,1,1,1,1,1,0,0,0,0,0,0,0,0,1,1,1,1,1,1,1,1,1,0,0,0,0,0,1,1,1,1,1,1,1,1,1,1,1,1,1,1,1,1,1,1,1,1,1,1,1,1,1,1,1,1,1,1,1,1,1,1,1,0,0,0,0,0,0,0,1,0,0,0,0,0,0,0,0,0,0,0,0,0,0,0,0,0,0,0,0,0,0,0,0,0,0,0,0,
		0,0,1,1,1,1,1,1,1,1,1,1,1,1,1,1,1,1,1,1,1,1,1,1,1,1,1,1,1,1,1,1,1,1,1,1,0,0,0,0,0,0,0,0,1,1,1,1,1,1,1,1,1,1,1,1,1,1,1,1,1,1,1,1,1,1,1,1,1,1,1,1,1,1,1,1,1,1,1,1,1,1,1,1,1,1,1,1,1,1,1,1,1,0,0,0,0,0,0,0,0,0,0,0,0,0,0,0,0,0,0,0,0,0,0,0,0,0,0,0,0,0,0,0,0,0,0,0,
		0,0,1,1,1,1,1,1,1,1,1,1,1,1,1,1,1,1,1,1,1,1,1,1,1,1,1,1,1,1,1,1,1,1,1,1,0,0,0,0,0,0,0,0,0,1,1,1,1,1,1,1,1,1,1,1,1,1,1,1,1,1,1,1,1,1,1,1,1,1,1,1,1,1,1,1,1,1,1,1,1,1,1,1,1,1,1,1,1,1,1,1,1,0,0,0,0,0,0,0,0,0,0,0,0,0,0,0,0,0,0,0,0,0,0,0,0,0,0,0,0,0,0,0,0,0,0,0,
		0,0,1,1,1,1,1,1,1,1,1,1,1,1,1,1,1,1,1,1,1,1,1,1,1,1,1,1,1,1,1,1,1,1,1,1,0,0,0,0,0,0,0,0,0,0,1,1,1,1,1,1,1,1,1,1,1,1,1,0,0,0,0,0,1,0,0,0,0,0,0,0,0,0,1,1,1,1,1,1,1,1,1,1,1,1,1,1,1,1,1,1,1,1,0,0,0,0,0,0,0,0,0,0,0,0,0,0,0,0,0,0,0,0,0,0,0,0,0,0,0,0,0,0,0,0,0,0,
		0,0,1,1,1,1,1,1,1,1,1,1,1,1,1,1,1,1,1,1,1,1,1,1,1,1,1,1,1,1,1,1,1,1,1,1,1,0,0,0,0,0,0,0,0,0,1,1,1,1,1,1,1,1,1,1,0,0,0,0,0,0,0,0,0,0,0,0,0,0,0,0,0,0,1,1,1,1,1,1,1,1,1,1,1,1,1,1,1,1,1,1,1,1,0,0,0,0,0,0,0,0,0,0,0,0,0,0,0,0,0,0,0,0,0,0,0,0,0,0,0,0,0,0,0,0,0,0,
		0,0,1,1,1,1,1,1,1,1,1,1,1,1,1,1,1,1,1,1,1,1,1,1,1,1,1,1,1,1,1,1,1,1,1,1,1,0,0,0,0,0,0,0,0,0,1,1,1,1,1,1,1,1,1,1,0,0,0,0,0,0,0,0,0,0,0,0,0,0,0,0,1,1,1,1,1,1,1,1,1,1,1,1,1,1,1,1,1,1,1,1,1,1,1,0,0,0,0,0,0,0,0,0,0,0,0,0,0,0,0,0,0,0,0,0,1,0,0,0,0,0,0,0,0,0,0,0,
		0,0,1,1,1,1,1,1,1,1,1,1,1,1,1,0,1,1,1,1,1,1,1,1,1,1,1,1,1,1,1,1,1,1,1,1,1,1,0,0,0,0,0,0,0,1,1,1,1,1,1,1,0,1,1,1,1,1,1,0,0,0,0,0,0,0,0,0,0,1,0,1,0,0,0,0,0,0,1,1,1,1,1,1,1,1,1,1,1,1,1,1,1,1,1,0,0,0,0,0,0,0,1,1,1,1,1,1,1,1,1,1,1,1,1,1,1,1,1,1,1,1,1,1,1,1,1,1,
		0,0,1,1,1,1,1,1,1,1,1,1,1,1,1,0,0,1,1,1,1,1,1,1,1,1,1,1,1,1,1,1,1,1,1,1,1,1,0,0,0,0,0,0,0,1,1,1,1,1,1,0,0,0,0,0,0,1,1,1,1,0,0,0,1,1,0,0,0,0,0,0,0,0,0,0,0,0,0,0,1,1,1,1,1,1,1,1,1,1,1,1,1,1,1,0,0,0,0,0,0,1,1,1,1,1,1,1,1,1,1,1,1,1,1,1,1,1,1,1,1,1,1,1,1,1,1,1,
		0,0,1,1,1,1,1,1,1,1,1,1,1,1,1,0,0,1,0,1,1,1,1,1,1,1,1,1,1,1,1,1,1,1,1,1,1,1,1,0,0,0,0,0,0,1,1,1,1,1,1,0,0,0,0,0,0,0,0,0,0,0,0,0,0,0,0,0,0,0,0,0,0,0,0,0,0,0,0,0,0,1,1,1,1,1,1,1,1,1,1,1,1,1,1,0,0,0,0,0,1,1,1,1,1,1,1,1,1,1,1,1,1,1,1,1,1,1,1,1,1,1,1,1,1,1,1,1,
		0,0,1,1,1,1,1,1,1,1,1,1,1,1,1,1,1,1,1,1,1,1,1,1,1,1,1,1,1,1,1,1,1,1,1,1,1,1,1,0,0,0,0,0,0,1,1,1,1,1,0,0,0,0,0,0,0,0,0,0,0,0,0,0,0,0,0,0,0,0,0,0,0,0,0,0,0,0,0,0,0,1,1,1,1,1,1,1,1,1,1,1,1,1,0,0,0,0,0,1,1,1,1,1,1,1,1,1,1,1,1,1,1,1,1,1,1,1,1,1,1,1,1,1,1,1,1,1,
		0,0,1,1,1,1,1,1,1,1,1,1,1,1,1,1,1,1,1,1,1,1,1,1,1,1,1,1,1,1,1,1,1,1,1,1,1,1,1,1,0,0,0,0,1,1,1,1,1,0,0,0,0,0,0,0,0,0,0,0,0,0,0,0,0,0,0,0,0,0,0,0,0,0,0,0,0,0,0,0,0,0,1,1,1,1,1,1,1,1,1,1,1,1,0,0,0,0,1,1,1,1,1,1,1,1,1,1,1,1,1,1,1,1,1,1,1,1,1,1,1,1,1,1,1,1,1,1,
		0,0,1,1,1,1,1,1,1,1,1,1,1,1,1,1,1,1,1,1,1,1,1,1,1,1,1,1,1,1,1,1,1,1,1,1,1,1,1,1,0,0,0,0,1,1,1,1,1,0,0,0,0,0,0,0,0,0,0,0,0,1,1,1,1,1,1,1,1,1,1,1,1,0,0,0,0,0,0,0,0,0,1,1,1,1,1,1,1,1,1,1,1,1,0,0,0,0,1,1,1,1,1,1,1,1,1,1,1,1,1,1,1,1,1,1,1,1,1,1,1,1,1,1,1,1,1,1,
		0,1,1,1,1,1,1,1,1,1,1,1,1,1,1,1,1,1,1,1,1,1,1,1,1,1,1,1,1,1,1,1,1,1,1,1,1,1,1,1,1,0,0,1,1,1,1,1,1,0,0,0,0,0,0,0,0,0,0,0,1,1,1,1,1,1,1,1,1,1,1,1,1,0,0,0,0,0,0,0,0,1,1,1,1,1,1,1,1,1,1,1,1,1,0,0,0,1,1,1,1,1,1,1,1,1,1,1,1,1,1,1,1,1,1,1,1,1,1,1,1,1,1,1,1,1,1,1,
		0,0,1,1,1,1,1,1,1,1,1,1,1,1,1,1,1,1,1,1,1,1,1,1,1,1,1,1,1,1,1,1,1,1,1,1,1,1,1,1,1,1,0,1,1,1,1,1,1,0,0,0,0,0,0,0,0,0,0,1,1,1,1,1,1,1,1,1,1,1,1,1,1,0,0,0,0,0,0,0,0,1,1,1,1,1,1,1,1,1,1,1,1,0,0,0,0,1,1,1,1,1,1,1,1,1,1,1,1,1,1,1,1,1,1,1,1,1,1,1,1,1,1,1,1,1,1,1,
		0,0,1,1,1,1,1,1,1,1,1,1,1,1,1,1,1,1,1,1,1,1,1,1,1,1,1,1,1,1,1,1,1,1,1,1,1,1,1,1,1,1,0,0,1,1,1,1,1,1,0,0,0,0,0,0,0,0,0,0,1,1,1,1,1,1,1,1,1,1,1,1,1,0,0,0,0,0,0,0,0,0,0,1,1,1,1,1,1,1,1,1,0,0,0,0,0,1,1,1,1,1,1,1,1,1,1,1,1,1,1,1,1,1,1,1,1,1,1,1,1,1,1,1,1,1,1,1,
		0,0,1,1,1,1,1,1,1,1,1,1,1,1,1,1,1,1,1,1,1,1,1,1,1,1,1,1,1,1,1,1,1,1,1,1,1,1,1,1,1,1,1,0,0,1,1,1,1,1,0,0,0,0,0,0,0,0,0,0,1,1,1,1,1,1,1,1,1,1,1,1,1,0,0,0,0,0,0,0,0,0,0,1,1,1,1,1,1,1,1,0,0,0,0,0,0,1,1,1,1,1,1,1,1,1,1,1,1,1,1,1,1,1,1,1,1,1,1,1,1,1,1,1,1,1,1,1,
		0,0,1,1,1,1,1,1,1,1,1,1,1,1,1,1,1,1,1,1,1,1,1,1,1,1,1,1,1,1,1,1,1,1,1,1,1,1,1,1,1,1,1,1,0,1,1,1,1,1,0,0,0,0,0,0,0,0,0,0,0,0,0,0,0,1,0,0,0,0,0,0,0,0,0,0,0,0,0,0,0,0,1,1,1,1,1,1,1,1,1,0,0,0,0,0,0,1,1,1,1,1,1,1,1,1,1,1,1,1,1,1,1,1,1,1,1,1,1,1,1,1,1,1,1,1,1,1,
		1,1,1,1,1,1,1,1,1,1,1,1,1,1,1,1,1,1,1,1,1,1,1,1,1,1,1,1,1,1,1,1,1,1,1,1,1,1,1,1,1,1,1,1,1,0,1,1,1,1,0,0,0,0,0,0,0,0,0,0,0,0,0,0,0,0,0,0,0,0,0,0,0,0,0,0,0,0,0,0,0,0,1,1,1,1,1,1,1,1,0,0,0,0,0,0,0,1,1,1,1,1,1,1,1,1,1,1,1,1,1,1,1,1,1,1,1,1,1,1,1,1,1,1,1,1,1,1,
		0,0,1,1,1,1,1,1,1,1,1,1,1,1,1,1,1,1,1,1,1,1,1,1,1,1,1,1,1,1,1,1,1,1,1,1,1,1,1,1,1,1,1,1,1,1,1,1,1,1,0,0,0,0,0,0,0,0,0,0,0,0,0,0,0,0,0,0,0,0,0,0,0,0,0,0,0,0,0,0,0,1,1,1,1,1,1,1,1,0,0,0,0,0,0,0,0,1,1,1,1,1,1,1,1,1,1,1,1,1,1,1,1,1,1,1,1,1,1,1,1,1,1,1,1,1,1,1,
		1,0,1,1,1,1,1,1,1,1,1,1,1,1,1,1,1,1,1,1,1,1,1,1,1,1,1,1,1,1,1,1,1,1,1,1,1,1,1,1,1,1,1,1,1,1,0,0,1,1,0,0,0,0,0,0,0,0,0,0,0,0,0,0,0,0,0,0,0,0,0,0,0,0,0,0,0,0,0,0,0,1,1,1,1,1,1,1,0,0,0,0,0,0,0,0,0,0,1,1,1,1,1,1,1,1,1,1,1,1,1,1,1,1,1,1,1,1,1,1,1,1,1,1,1,1,1,1,
		1,1,1,1,1,1,1,1,1,1,1,1,1,1,1,1,1,1,1,1,1,1,1,1,1,1,1,1,1,1,1,1,1,1,1,1,1,1,1,1,1,1,1,1,1,1,0,0,0,1,0,0,0,0,0,0,0,0,0,0,0,0,0,0,0,0,0,0,0,0,0,0,0,0,0,0,0,0,0,0,1,1,1,1,1,1,1,0,0,1,0,0,0,0,0,0,0,0,0,0,0,1,1,0,0,0,0,0,0,0,0,0,1,1,1,1,1,1,1,1,1,1,1,1,1,1,1,1,
		1,1,1,1,1,1,1,1,1,1,1,1,1,1,1,1,1,1,1,1,1,1,1,1,1,1,1,1,1,1,1,1,1,1,1,1,1,1,1,1,1,1,1,1,1,1,0,0,0,0,1,0,1,0,0,0,0,0,0,0,0,0,0,0,0,0,0,0,0,0,0,0,0,0,0,0,1,1,1,1,1,1,1,1,1,1,1,1,1,1,0,0,0,0,0,0,0,0,0,0,0,0,0,0,0,0,0,0,0,0,0,0,0,0,0,1,1,1,1,1,1,1,1,1,1,1,1,1,
		1,1,1,1,1,1,1,1,1,1,1,1,1,1,1,1,1,1,1,1,1,1,1,1,1,1,1,1,1,1,1,1,1,1,1,1,1,1,1,1,1,1,1,1,1,1,0,0,0,0,0,1,1,1,0,0,0,0,0,0,0,0,0,0,0,0,0,0,0,0,0,0,0,0,1,1,1,1,1,1,1,1,1,1,1,1,1,1,1,1,0,0,0,0,0,0,0,0,0,0,0,0,0,0,0,0,0,0,0,0,0,0,0,0,0,0,0,0,1,1,1,1,1,1,1,1,1,1,
		1,1,1,1,1,1,1,1,1,1,1,1,1,1,1,1,1,1,1,1,1,1,1,1,1,1,1,1,1,1,1,1,1,1,1,1,1,1,1,1,1,1,1,1,1,1,0,0,0,0,0,1,1,1,1,1,0,0,0,0,0,0,0,0,0,0,1,1,1,1,1,1,1,1,1,1,1,1,1,1,1,1,1,1,1,1,1,1,1,1,0,0,0,0,0,0,0,0,0,0,0,0,0,0,0,0,0,0,0,0,0,0,0,0,0,0,0,0,0,0,1,0,0,0,1,1,1,1,
		1,1,1,1,1,1,1,1,1,1,1,1,1,1,1,1,1,1,1,1,1,1,1,1,1,1,1,1,1,1,1,1,1,1,1,1,1,1,1,1,1,1,1,1,1,1,0,0,0,0,0,1,1,1,1,1,1,1,1,1,1,1,1,1,1,1,1,1,1,1,1,1,1,1,1,1,1,1,1,1,1,1,1,1,1,1,1,1,1,0,0,0,0,0,0,0,0,0,0,0,0,0,0,0,0,0,0,0,0,0,0,0,0,0,0,0,0,0,0,0,0,0,0,0,0,0,0,0,
		1,1,1,1,1,1,1,1,1,1,1,1,1,1,1,1,1,1,1,1,1,1,1,1,1,1,1,1,1,1,1,1,1,1,1,1,1,1,1,1,0,0,0,0,0,0,0,0,0,0,0,0,1,1,1,1,1,1,1,1,1,1,1,1,1,1,1,1,1,1,1,1,1,1,1,1,1,1,1,1,1,1,1,1,1,1,1,1,1,0,0,0,0,0,0,0,0,0,0,0,0,0,0,0,0,0,0,0,0,0,0,0,0,0,0,0,0,0,0,0,0,0,0,0,0,0,0,0,
		1,1,1,1,1,1,1,1,1,1,1,1,1,1,1,1,1,1,1,1,1,1,1,1,1,1,1,1,1,1,1,1,1,1,1,1,1,0,0,0,0,0,0,0,0,0,0,0,0,0,0,0,1,1,1,1,1,1,1,1,1,1,1,1,1,1,1,1,1,1,1,1,1,1,1,1,1,1,1,1,1,1,1,1,1,1,1,1,1,0,0,0,0,0,0,0,0,0,0,0,0,0,0,0,0,0,0,0,0,0,0,0,0,0,0,0,0,0,0,0,0,0,0,0,0,0,0,0,
		1,1,1,1,1,1,1,1,1,1,1,1,1,1,1,1,1,1,1,1,1,1,1,1,1,1,1,1,1,1,1,1,0,0,0,0,0,0,0,0,0,0,0,0,0,0,0,0,0,0,0,0,0,1,1,1,1,1,1,1,1,1,1,1,1,1,1,1,1,1,1,1,1,1,1,1,1,1,1,1,1,1,1,1,1,1,1,1,0,0,0,0,0,0,0,0,0,0,0,0,0,0,0,0,0,0,0,0,0,0,0,0,0,0,0,0,0,0,0,0,0,0,0,0,0,0,0,0,
		1,1,1,1,1,1,1,1,1,1,1,1,1,0,0,1,0,1,1,1,1,1,1,1,1,1,1,1,1,1,1,0,0,0,0,0,0,0,0,0,0,0,0,0,0,0,0,0,0,0,0,0,0,0,1,1,1,1,1,1,1,1,1,1,1,1,1,1,1,1,1,1,1,1,1,1,1,1,1,1,1,1,1,1,1,1,1,0,0,0,0,0,0,0,0,0,0,0,0,0,0,0,0,0,0,0,0,0,0,0,0,0,0,0,0,0,0,0,0,0,0,0,0,0,0,0,0,0,
		1,1,1,1,1,1,1,1,1,1,1,0,0,0,0,1,0,1,1,1,1,1,1,1,1,1,1,1,1,1,1,0,0,0,0,0,0,0,0,0,0,0,0,0,0,0,0,0,0,0,0,0,0,0,0,0,1,1,1,1,1,1,1,1,1,1,1,1,1,1,1,1,1,1,1,1,1,1,1,1,1,1,1,1,1,1,0,0,0,0,0,0,0,0,0,0,0,0,0,0,0,0,0,0,0,0,0,0,0,0,0,0,0,0,0,0,0,0,0,0,0,0,0,0,0,0,0,0,
		1,1,1,1,1,1,1,1,1,1,1,0,0,0,0,0,1,1,1,1,1,1,1,1,1,1,1,1,1,1,1,0,0,0,0,0,0,0,0,0,0,0,0,1,0,0,0,0,0,0,0,0,0,0,0,0,0,1,1,1,1,1,1,1,1,1,1,1,1,1,1,1,1,1,1,1,1,1,1,1,1,1,1,1,1,0,0,0,0,0,0,0,0,0,0,0,0,0,0,0,0,0,0,0,0,0,0,0,0,0,0,0,0,0,0,0,0,0,0,0,0,0,0,0,0,0,0,0,
		1,1,1,1,1,1,1,1,1,1,0,0,0,0,0,0,1,1,1,1,1,1,1,1,1,1,1,1,1,1,0,0,0,0,0,0,0,0,0,0,0,0,0,0,0,0,0,0,0,0,0,0,0,0,0,0,0,0,1,1,1,1,1,1,1,1,1,1,1,1,1,1,1,1,1,1,1,1,1,1,1,1,1,0,0,0,0,0,0,0,0,0,0,0,0,0,0,0,0,0,0,0,0,0,0,0,0,0,0,0,0,0,0,0,0,0,0,0,0,0,0,0,0,0,0,0,0,0,
		1,1,1,1,1,1,1,0,0,0,0,0,0,0,0,0,0,1,1,0,0,0,0,1,1,1,1,1,0,0,0,0,0,0,0,0,0,1,0,0,0,0,1,0,0,0,0,0,0,0,0,0,0,0,0,0,0,0,1,1,1,1,1,1,1,1,1,1,1,1,1,1,1,1,1,1,1,1,1,1,1,1,0,0,0,0,0,0,0,0,0,0,0,0,0,0,0,0,0,0,0,0,0,0,0,0,0,0,0,0,0,0,0,0,0,0,0,0,0,0,0,0,0,0,0,0,0,0,
		1,1,1,1,1,1,1,0,0,0,0,0,0,0,0,0,0,0,0,0,0,0,0,0,0,0,1,1,0,0,0,0,0,0,0,0,1,1,1,1,1,1,1,0,0,0,0,0,0,0,0,0,0,0,0,0,0,0,0,1,0,0,0,1,1,1,1,1,1,1,1,1,1,1,1,1,1,1,1,1,1,0,0,0,0,0,0,0,0,0,0,0,0,0,0,0,0,0,0,0,0,0,0,0,0,0,0,0,0,0,0,0,0,0,0,0,0,0,0,0,0,0,0,0,0,0,0,0,
		1,1,1,1,1,0,0,0,0,0,0,0,0,0,0,0,0,0,0,0,0,0,0,0,0,0,1,0,0,0,0,0,0,0,1,1,0,0,0,0,0,0,0,0,0,0,0,0,0,0,0,0,0,0,0,0,0,0,0,0,0,0,0,1,1,1,1,1,1,1,1,1,1,1,1,1,1,1,1,1,1,0,0,0,0,0,0,0,0,0,0,0,0,0,0,0,0,0,0,0,0,0,0,0,0,0,0,0,0,0,0,0,0,0,0,0,0,0,0,0,0,0,0,0,0,0,0,0,
		1,1,1,1,1,1,0,0,0,0,0,0,0,0,0,0,0,0,0,0,0,0,0,0,0,0,1,0,0,0,0,0,0,1,1,0,0,0,0,0,0,0,0,0,0,0,0,0,0,0,0,0,0,0,0,0,0,0,0,0,0,0,0,0,1,1,1,1,1,1,1,1,1,1,1,1,1,1,1,1,1,0,0,0,0,0,0,0,0,0,0,0,0,0,0,0,0,0,0,0,0,0,0,0,0,0,0,0,0,0,0,0,0,0,0,0,0,0,0,0,0,0,0,0,0,0,0,0,
		1,1,1,1,1,1,0,0,0,0,0,0,0,0,0,0,0,0,0,0,0,0,0,0,0,0,1,0,0,0,0,0,0,0,0,0,0,0,0,0,0,0,0,0,0,0,0,0,0,0,0,0,0,0,0,0,0,0,0,0,0,0,0,0,0,1,1,1,1,1,1,1,1,1,1,1,1,1,1,1,0,0,0,0,0,0,0,0,0,0,0,0,0,0,0,0,0,0,0,0,0,0,0,0,0,0,0,0,0,0,0,0,0,0,0,0,0,0,0,0,0,0,0,0,0,0,0,0,
		1,1,1,1,1,1,0,0,0,0,0,0,0,0,0,0,0,0,0,0,0,0,0,0,0,0,1,0,0,0,0,0,0,0,0,0,0,0,0,0,0,0,0,0,0,0,0,0,0,0,0,0,0,0,0,0,0,0,0,0,0,0,0,0,0,1,1,1,1,1,1,1,1,1,1,1,1,1,1,0,0,0,0,0,0,0,0,0,0,0,0,0,0,0,0,0,0,0,0,0,0,0,0,0,0,0,0,0,0,0,0,0,0,0,0,0,0,0,0,0,0,0,0,0,0,0,0,0,
		1,1,1,1,1,0,0,0,0,0,0,0,0,0,0,0,0,0,0,0,0,0,0,0,0,0,1,0,0,0,0,0,0,0,0,0,0,0,0,0,0,0,0,0,0,0,0,0,0,0,0,0,0,0,0,0,0,0,0,0,0,0,0,0,0,1,1,1,1,1,1,1,1,1,1,1,1,1,1,0,0,0,0,0,0,0,0,0,0,0,0,0,0,0,0,0,0,0,0,0,0,0,0,0,0,0,0,0,0,0,0,0,0,0,0,0,0,0,0,0,0,0,0,0,0,0,0,0,
		1,1,1,1,1,0,0,0,0,0,0,0,0,0,0,0,0,0,0,0,0,0,0,0,0,0,0,0,0,0,0,0,0,0,0,0,0,0,0,0,0,0,0,0,0,0,0,0,0,0,0,0,0,0,0,0,0,0,0,0,0,0,0,0,0,0,1,1,1,1,1,1,1,1,1,1,1,1,1,0,0,0,0,0,0,0,0,0,0,0,0,0,0,0,0,0,0,0,0,0,0,0,0,0,0,0,0,0,0,0,0,0,0,0,0,0,0,0,0,0,0,0,0,0,0,0,0,0,
		1,1,1,1,1,0,0,0,0,0,0,0,0,0,0,0,0,0,0,0,0,0,0,0,0,0,0,0,0,0,0,0,0,0,0,0,0,0,0,0,0,0,0,0,0,0,0,0,0,0,0,0,0,0,0,0,0,0,0,0,0,0,0,0,0,0,1,1,1,1,1,1,1,1,1,1,1,1,1,0,0,0,0,0,0,0,0,0,0,0,0,0,0,0,0,0,0,0,0,0,0,0,0,0,0,0,0,0,0,0,0,0,0,0,0,0,0,0,0,0,0,0,0,0,0,0,0,0,
		1,1,1,1,0,0,0,0,0,0,0,0,0,0,0,0,0,0,0,0,0,0,0,0,0,0,0,0,0,0,0,0,0,0,0,0,0,0,0,0,0,0,0,0,0,0,0,0,0,0,0,0,0,0,0,0,0,0,0,0,0,0,0,0,0,1,1,1,1,1,1,1,1,1,1,1,1,1,1,0,0,0,0,0,0,0,0,0,0,0,0,0,0,0,0,0,0,0,0,0,0,0,0,0,0,0,0,0,0,0,0,0,0,0,0,0,0,0,0,0,0,0,0,0,0,0,0,0,
		1,1,1,0,0,0,0,0,0,0,0,0,0,0,0,0,0,0,0,0,0,0,0,0,0,0,0,0,0,0,0,0,0,0,0,0,0,0,0,0,0,0,0,0,0,0,0,0,0,0,0,0,0,0,0,0,0,0,0,0,0,0,0,0,0,1,1,1,1,1,1,1,1,1,1,1,1,1,0,0,0,0,0,0,0,0,0,0,0,0,0,0,0,0,0,0,0,0,0,0,0,0,0,0,0,0,0,0,0,0,0,0,0,0,0,0,0,0,0,0,0,0,0,0,0,0,0,0,
		1,1,1,0,0,0,0,0,0,0,0,0,0,0,0,0,0,0,0,0,0,0,0,0,0,0,0,0,0,0,0,0,0,0,0,0,0,0,0,0,0,0,0,0,0,0,0,0,0,0,0,0,0,0,0,0,0,0,0,0,0,0,0,0,0,1,1,1,1,1,1,1,1,1,1,1,1,1,0,0,0,0,0,0,0,0,0,0,0,0,0,0,0,0,0,0,0,0,0,0,0,0,0,0,0,0,0,0,0,0,0,0,0,0,0,0,0,0,0,0,0,0,0,0,0,0,0,0,
		1,1,1,0,1,0,0,1,0,0,0,0,0,0,0,0,0,0,0,0,0,0,0,0,0,0,0,0,0,0,0,0,0,0,0,0,0,0,0,0,0,0,0,0,0,0,0,0,0,0,0,0,0,0,0,0,0,0,0,0,0,0,0,0,0,1,1,1,1,1,1,1,1,1,1,1,1,1,0,0,0,0,0,0,0,0,0,0,0,0,0,0,0,0,0,0,0,0,0,0,0,0,0,0,0,0,0,0,0,0,0,0,0,0,0,0,0,0,0,0,0,0,0,0,0,0,0,0,
		1,1,1,0,1,1,0,1,0,0,0,0,0,0,0,0,0,0,0,0,0,0,0,0,0,0,0,0,0,0,0,0,0,0,0,0,0,0,0,0,0,0,0,0,0,0,0,0,0,0,0,0,0,0,0,0,0,0,0,0,0,0,0,0,0,0,1,1,1,1,1,1,1,1,1,1,1,0,0,0,0,0,0,0,0,0,0,0,0,0,0,0,0,0,0,0,0,0,0,0,0,0,0,0,0,0,0,0,0,0,0,0,0,0,0,0,0,0,0,0,0,0,0,0,0,0,0,0,
		1,1,1,1,1,0,0,0,0,0,0,0,0,0,0,0,0,0,0,0,0,0,0,0,0,0,0,0,0,0,0,0,0,0,0,0,0,0,0,0,0,0,0,0,0,0,0,0,0,0,0,0,0,0,0,0,0,0,0,0,0,0,0,0,0,0,1,1,1,1,1,1,1,1,1,1,0,0,0,0,0,0,0,0,0,0,0,0,0,0,0,0,0,0,0,0,0,0,0,0,0,0,0,0,0,0,0,0,0,0,0,0,0,0,0,0,0,0,0,0,0,0,0,0,0,0,0,0,
		1,1,1,1,0,0,0,0,0,0,0,0,0,0,0,0,0,0,0,0,0,0,0,0,0,0,0,0,0,0,0,0,0,0,0,0,0,0,0,0,0,0,0,0,0,0,0,0,0,0,0,0,0,0,0,0,0,0,0,0,0,0,0,0,0,0,0,1,1,1,1,1,1,1,1,1,0,0,0,0,0,0,0,0,0,0,0,0,0,0,0,0,0,0,0,0,0,0,0,0,0,0,0,0,0,0,0,0,0,0,0,0,0,0,0,0,0,0,0,0,0,0,0,0,0,0,0,0,
		1,1,1,0,0,0,0,0,0,0,0,0,0,0,0,0,0,0,0,0,0,0,0,0,0,0,0,0,0,0,0,0,0,0,0,0,0,0,0,0,0,0,0,0,0,0,0,0,0,0,0,0,0,0,0,0,0,0,0,0,0,0,0,0,0,0,0,0,0,0,0,0,0,0,0,0,0,0,0,0,0,0,0,0,0,0,0,0,0,0,0,0,0,0,0,0,0,0,0,0,0,0,0,0,0,0,0,0,0,0,0,0,0,0,0,0,0,0,0,0,0,0,0,0,0,0,0,0,
		1,1,1,1,0,0,0,0,0,0,0,0,0,0,0,0,0,0,0,0,0,0,0,0,0,0,0,0,0,0,0,0,0,0,0,0,0,0,0,0,0,0,0,0,0,0,0,0,0,0,0,0,0,0,0,0,0,0,0,0,0,0,0,0,0,0,0,0,0,0,0,0,0,0,0,0,0,0,0,0,0,0,0,0,0,0,0,0,0,0,0,0,0,0,0,0,0,0,0,0,0,0,0,0,0,0,0,0,0,0,0,0,0,0,0,0,0,0,0,0,0,0,0,0,0,0,0,0,
		0,1,1,0,0,0,0,0,0,0,0,0,0,0,0,0,0,0,0,0,0,0,0,0,0,0,0,0,0,0,0,0,0,0,0,0,0,0,0,0,0,0,0,0,0,0,0,0,0,0,0,0,0,0,0,0,0,0,0,0,0,0,0,0,0,0,0,0,0,0,0,0,0,0,0,0,0,0,0,0,0,0,0,0,0,0,0,0,0,0,0,0,0,0,0,0,0,0,0,0,0,0,0,0,0,0,0,0,0,0,0,0,0,0,0,0,0,0,0,0,0,0,0,0,0,0,0,0,
		0,1,0,0,0,0,0,0,0,0,0,0,0,0,0,0,0,0,0,0,0,0,0,0,0,0,0,0,0,0,0,0,0,0,0,0,0,0,0,0,0,0,0,0,0,0,0,0,0,0,0,0,0,0,0,0,0,0,0,0,0,0,0,0,0,0,0,0,0,0,0,0,0,0,0,0,0,0,0,0,0,0,0,0,0,0,0,0,0,0,0,0,0,0,0,0,0,0,0,0,0,0,0,0,0,0,0,0,0,0,0,0,0,0,0,0,0,0,0,0,0,0,0,0,0,0,0,0,
		0,0,0,0,0,0,0,0,0,0,0,0,0,0,0,0,0,0,0,0,0,0,0,0,0,0,0,0,0,0,0,0,0,0,0,0,0,0,0,0,0,0,0,0,0,0,0,0,0,0,0,0,0,0,0,0,0,0,0,0,0,0,0,0,0,0,0,0,0,0,0,0,0,0,0,0,0,0,0,0,0,0,0,0,0,0,0,0,0,0,0,0,0,0,0,0,0,0,0,0,0,0,0,0,0,0,0,0,0,0,0,0,0,0,0,0,0,0,0,0,0,0,0,0,0,0,0,0,
		0,0,0,0,0,0,0,0,0,0,0,0,0,0,0,0,0,0,0,0,0,0,0,0,0,0,0,0,0,0,0,0,0,0,0,0,0,0,0,0,0,0,0,0,0,0,0,0,0,0,0,0,0,0,0,0,0,0,0,0,0,0,0,0,0,0,0,0,0,0,0,0,0,0,0,0,0,0,0,0,0,0,0,0,0,0,0,0,0,0,0,0,0,0,0,0,0,0,0,0,0,0,0,0,0,0,0,0,0,0,0,0,0,0,0,0,0,0,0,0,0,0,0,0,0,0,0,0,
		0,0,0,0,0,0,0,0,0,0,0,0,0,0,0,0,0,0,0,0,0,0,0,0,0,0,0,0,0,0,0,0,0,0,0,0,0,0,0,0,0,0,0,0,0,0,0,0,0,0,0,0,0,0,0,0,0,0,0,0,0,0,0,0,0,0,0,0,0,0,0,0,0,0,0,0,0,0,0,0,0,0,0,0,0,0,0,0,0,0,0,0,0,0,0,0,0,0,0,0,0,0,0,0,0,0,0,0,0,0,0,0,0,0,0,0,0,0,0,0,0,0,0,0,0,0,0,0,
		0,0,0,0,0,0,0,0,0,0,0,0,0,0,0,0,0,0,0,0,0,0,0,0,0,0,0,0,0,0,0,0,0,0,0,0,0,0,0,0,0,0,0,0,0,0,0,0,0,0,0,0,0,0,0,0,0,0,0,0,0,0,0,0,0,0,0,0,0,0,0,0,0,0,0,0,0,0,0,0,0,0,0,0,0,0,0,0,0,0,0,0,0,0,0,0,0,0,0,0,0,0,0,0,0,0,0,0,0,0,0,0,0,0,0,0,0,0,0,0,0,0,0,0,0,0,0,0,
		0,0,0,0,0,0,0,0,0,0,0,0,0,0,0,0,0,0,0,0,0,0,0,0,0,0,0,0,0,0,0,0,0,0,0,0,0,0,0,0,0,0,0,0,0,0,0,0,0,0,0,0,0,0,0,0,0,0,0,0,0,0,0,0,0,0,0,0,0,0,0,0,0,0,0,0,0,0,0,0,0,0,0,0,0,0,0,0,0,0,0,0,0,0,0,0,0,0,0,0,0,0,0,0,0,0,0,0,0,0,0,0,0,0,0,0,0,0,0,0,0,0,0,0,0,0,0,0,
		0,0,0,0,0,0,0,0,0,0,0,0,0,0,0,0,0,0,0,0,0,0,0,0,0,0,0,0,0,0,0,0,0,0,0,0,0,0,0,0,0,0,0,0,0,0,0,0,0,0,0,0,0,0,0,0,0,0,0,0,0,0,0,0,0,0,0,0,0,0,0,0,0,0,0,0,0,0,0,0,0,0,0,0,0,0,0,0,0,0,0,0,0,0,0,0,0,0,0,0,0,0,0,0,0,0,0,0,0,0,0,0,0,0,0,0,0,0,0,0,0,0,0,0,0,0,0,0,
		0,0,0,0,0,0,0,0,0,0,0,0,0,0,0,0,0,0,0,0,0,0,0,0,0,0,0,0,0,0,0,0,0,0,0,0,0,0,0,0,0,0,0,0,0,0,0,0,0,0,0,0,0,0,0,0,0,0,0,0,0,0,0,0,0,0,0,0,0,0,0,0,0,0,0,0,0,0,0,0,0,0,0,0,0,0,0,0,0,0,0,0,0,0,0,0,0,0,0,0,0,0,0,0,0,0,0,0,0,0,0,0,0,0,0,0,0,0,0,0,0,0,0,0,0,0,0,0,
		0,0,0,0,0,0,0,0,0,0,0,0,0,0,0,0,0,0,0,0,0,0,0,0,0,0,0,0,0,0,0,0,0,0,0,0,0,0,0,0,0,0,0,0,0,0,0,0,0,0,0,0,0,0,0,0,0,0,0,0,0,0,0,0,0,0,0,0,0,0,0,0,0,0,0,0,0,0,0,0,0,0,0,0,0,0,0,0,0,0,0,0,0,0,0,0,0,0,0,0,0,0,0,0,0,0,0,0,0,0,0,0,0,0,0,0,0,0,0,0,0,0,0,0,0,0,0,0,
		0,0,0,0,0,0,0,0,0,0,0,0,0,0,0,0,0,0,0,0,0,0,0,0,0,0,0,0,0,0,0,0,0,0,0,0,0,0,0,0,0,0,0,0,0,0,0,0,0,0,0,0,0,0,0,0,0,0,0,0,0,0,0,0,0,0,0,0,0,0,0,0,0,0,0,0,0,0,0,0,0,0,0,0,0,0,0,0,0,0,0,0,0,0,0,0,0,0,0,0,0,0,0,0,0,0,0,0,0,0,0,0,0,0,0,0,0,0,0,0,0,0,0,0,0,0,0,0,
		0,0,0,0,0,0,0,0,0,0,0,0,0,0,0,0,0,0,0,0,0,0,0,0,0,0,0,0,0,0,0,0,0,0,0,0,0,0,0,0,0,0,0,0,0,0,0,0,0,0,0,0,0,0,0,0,0,0,0,0,0,0,0,0,0,0,0,0,0,0,0,0,0,0,0,0,0,0,0,0,0,0,0,0,0,0,0,0,0,0,0,0,0,0,0,0,0,0,0,0,0,0,0,0,0,0,0,0,0,0,0,0,0,0,0,0,0,0,0,0,0,0,0,0,0,0,0,0,
		0,0,0,0,0,0,0,0,0,0,0,0,0,0,0,0,0,0,0,0,0,0,0,0,0,0,0,0,0,0,0,0,0,0,0,0,0,0,0,0,0,0,0,0,0,0,0,0,0,0,0,0,0,0,0,0,0,0,0,0,0,0,0,0,0,0,0,0,0,0,0,0,0,0,0,0,0,0,0,0,0,0,0,0,0,0,0,0,0,0,0,0,0,0,0,0,0,0,0,0,0,0,0,0,0,0,0,0,0,0,0,0,0,0,0,0,0,0,0,0,0,0,0,0,0,0,0,0,
		0,0,0,0,0,0,0,0,0,0,0,0,0,0,0,0,0,0,0,0,0,0,0,0,0,0,0,0,0,0,0,0,0,0,0,0,0,0,0,0,0,0,0,0,0,0,0,0,0,0,0,0,0,0,0,0,0,0,0,0,0,0,0,0,0,0,0,0,0,0,0,0,0,0,0,0,0,0,0,0,0,0,0,0,0,0,0,0,0,0,0,0,0,0,0,0,0,0,0,0,0,0,0,0,0,0,0,0,0,0,0,0,0,0,0,0,0,0,0,0,0,0,0,0,0,0,0,0,
		0,0,0,0,0,0,0,0,0,0,0,0,0,0,0,0,0,0,0,0,0,0,0,0,0,0,0,0,0,0,0,0,0,0,0,0,0,0,0,0,0,0,0,0,0,0,0,0,0,0,0,0,0,0,0,0,0,0,0,0,0,0,0,0,0,0,0,0,0,0,0,0,0,1,1,1,1,1,1,1,1,0,0,0,0,0,0,0,0,0,0,0,0,0,0,1,1,1,0,0,0,0,0,0,0,0,0,0,0,0,0,0,0,0,0,0,0,0,0,0,0,0,0,0,0,0,0,0,
		0,0,0,0,0,0,0,0,0,0,0,0,0,0,0,0,0,0,0,0,0,0,0,0,0,0,0,0,0,0,0,0,0,0,0,0,0,0,0,0,0,0,0,0,0,0,0,0,0,0,0,0,0,0,0,0,0,0,0,0,0,0,0,0,0,0,0,0,0,1,0,0,1,1,1,1,1,1,1,1,1,1,0,0,0,0,0,0,1,1,0,0,0,1,1,1,1,0,0,0,0,0,0,0,0,0,0,0,0,0,0,0,0,0,0,0,0,0,0,0,0,0,0,0,0,0,0,0,
		0,0,0,0,0,0,0,0,0,0,0,0,0,0,0,0,0,0,0,0,0,0,0,0,0,0,0,0,0,0,0,0,0,0,0,0,0,0,0,0,0,0,0,0,0,0,0,0,0,0,0,0,0,0,0,0,0,0,0,0,0,0,0,0,0,0,0,0,1,1,1,1,1,1,1,1,1,1,1,1,1,1,1,1,1,1,1,1,1,0,0,0,0,0,0,0,0,0,0,0,0,0,0,0,0,0,0,0,0,0,0,0,0,0,0,0,0,0,0,0,0,0,0,0,0,0,0,0,
		0,0,0,0,0,0,0,0,0,0,0,0,0,0,0,0,0,0,0,0,0,0,0,0,0,0,0,0,0,0,0,0,0,0,0,0,0,0,0,0,0,0,0,0,0,0,0,0,0,0,0,0,0,0,0,0,0,0,0,0,0,1,1,0,0,0,0,1,1,1,1,1,1,1,1,1,1,1,1,1,1,1,1,1,1,1,1,0,0,0,0,0,0,0,0,0,0,0,0,0,0,0,0,0,0,0,0,0,0,0,0,0,0,0,0,0,0,0,0,0,0,0,0,0,0,0,0,0,
		0,0,0,0,0,0,0,0,0,0,0,0,0,0,0,0,0,0,0,0,0,0,0,0,0,0,0,0,0,0,0,0,0,0,0,0,0,0,0,0,0,0,0,0,0,0,0,0,0,0,0,0,0,0,0,0,0,0,0,0,0,0,0,1,1,1,1,1,1,1,1,1,1,1,1,1,1,1,1,1,1,1,1,1,1,0,0,0,0,0,0,0,0,0,0,0,0,0,0,0,0,0,0,0,0,0,0,0,0,0,0,0,0,0,0,0,0,0,0,0,0,0,0,0,0,0,0,0,

};

/* USER CODE END Includes */

/* USER CODE BEGIN PTD */
SPI_HandleTypeDef hspi1;

UART_HandleTypeDef huart1;
#define COLORED      0
#define UNCOLORED    1
/* USER CODE BEGIN PV */

/* USER CODE END PV */

/* Private function prototypes -----------------------------------------------*/

/* USER CODE END PTD */

SPI_HandleTypeDef hspi1;

UART_HandleTypeDef huart1;

void SystemClock_Config(void);
static void MX_GPIO_Init(void);
static void MX_SPI1_Init(void);
static void MX_USART1_UART_Init(void);

int main(void)
{
  /* USER CODE BEGIN 1 */
	unsigned char* frame_buffer = (unsigned char*)malloc(EPD_WIDTH * EPD_HEIGHT / 8);

  /* USER CODE END 1 */

  /* MCU Configuration--------------------------------------------------------*/

  /* Reset of all peripherals, Initializes the Flash interface and the Systick. */
  HAL_Init();

  /* Configure the system clock */
  SystemClock_Config();

  /* Initialize all configured peripherals */
  MX_GPIO_Init();
  MX_SPI1_Init();
  MX_USART1_UART_Init();
  /* USER CODE BEGIN 2 */
  EPD epd;
  EPD_Init(&epd);
    if (EPD_Init(&epd) != 0) {
        printf("e-Paper init failed\n");
        return -1;
      }

      Paint paint;
      Paint_Init(&paint, frame_buffer, epd.width, epd.height);
      Paint_Clear(&paint, UNCOLORED);

      /* Draw something to the frame buffer */
      /* For simplicity, the arguments are explicit numerical coordinates */
      Paint_SetRotate(&paint, ROTATE_0);
      Paint_DrawStringAt(&paint, 4, 50, "TZ", &Font20, COLORED);
      Paint_DrawRectangle(&paint, 10, 130, 50, 180, COLORED);
      Paint_DrawLine(&paint, 10, 130, 50, 180, COLORED);
      Paint_DrawLine(&paint, 50, 130, 10, 180, COLORED);
      Paint_DrawCircle(&paint, 100, 150, 25, COLORED);
      Paint_DrawFilledRectangle(&paint, 10, 200, 50, 250, COLORED);
      Paint_DrawFilledRectangle(&paint, 0, 76, 176, 96, COLORED);
      Paint_DrawFilledCircle(&paint, 100, 220, 25, COLORED);
      Paint_DrawStringAt(&paint, 18, 80, "NB!", &Font16, UNCOLORED);

      Paint_Clear(&paint, UNCOLORED);
  /* USER CODE END 2 */

  /* Infinite loop */
      for (int i = 0; i <sizeof(qie); i++){
          		if (qie[i] == 1){
          		   Paint_DrawPixel(&paint, i%128,i/128,COLORED);
          }

          }

          /* USER CODE END 2 */

          /* Infinite loop */
          EPD_DisplayFrame(&epd, frame_buffer);

}

void SystemClock_Config(void)
{
  RCC_OscInitTypeDef RCC_OscInitStruct = {0};
  RCC_ClkInitTypeDef RCC_ClkInitStruct = {0};

  /** Configure the main internal regulator output voltage
  */
  __HAL_RCC_PWR_CLK_ENABLE();
  __HAL_PWR_VOLTAGESCALING_CONFIG(PWR_REGULATOR_VOLTAGE_SCALE1);
  /** Initializes the CPU, AHB and APB busses clocks
  */
  RCC_OscInitStruct.OscillatorType = RCC_OSCILLATORTYPE_HSI;
  RCC_OscInitStruct.HSIState = RCC_HSI_ON;
  RCC_OscInitStruct.HSICalibrationValue = RCC_HSICALIBRATION_DEFAULT;
  RCC_OscInitStruct.PLL.PLLState = RCC_PLL_ON;
  RCC_OscInitStruct.PLL.PLLSource = RCC_PLLSOURCE_HSI;
  RCC_OscInitStruct.PLL.PLLM = 8;
  RCC_OscInitStruct.PLL.PLLN = 96;
  RCC_OscInitStruct.PLL.PLLP = RCC_PLLP_DIV2;
  RCC_OscInitStruct.PLL.PLLQ = 8;
  RCC_OscInitStruct.PLL.PLLR = 2;
  if (HAL_RCC_OscConfig(&RCC_OscInitStruct) != HAL_OK)
  {
    Error_Handler();
  }
  /** Initializes the CPU, AHB and APB busses clocks
  */
  RCC_ClkInitStruct.ClockType = RCC_CLOCKTYPE_HCLK|RCC_CLOCKTYPE_SYSCLK
                              |RCC_CLOCKTYPE_PCLK1|RCC_CLOCKTYPE_PCLK2;
  RCC_ClkInitStruct.SYSCLKSource = RCC_SYSCLKSOURCE_PLLCLK;
  RCC_ClkInitStruct.AHBCLKDivider = RCC_SYSCLK_DIV2;
  RCC_ClkInitStruct.APB1CLKDivider = RCC_HCLK_DIV1;
  RCC_ClkInitStruct.APB2CLKDivider = RCC_HCLK_DIV1;

  if (HAL_RCC_ClockConfig(&RCC_ClkInitStruct, FLASH_LATENCY_1) != HAL_OK)
  {
    Error_Handler();
  }
}

static void MX_SPI1_Init(void)
{

  /* SPI1 parameter configuration*/
  hspi1.Instance = SPI1;
  hspi1.Init.Mode = SPI_MODE_MASTER;
  hspi1.Init.Direction = SPI_DIRECTION_2LINES;
  hspi1.Init.DataSize = SPI_DATASIZE_8BIT;
  hspi1.Init.CLKPolarity = SPI_POLARITY_LOW;
  hspi1.Init.CLKPhase = SPI_PHASE_1EDGE;
  hspi1.Init.NSS = SPI_NSS_SOFT;
  hspi1.Init.BaudRatePrescaler = SPI_BAUDRATEPRESCALER_2;
  hspi1.Init.FirstBit = SPI_FIRSTBIT_MSB;
  hspi1.Init.TIMode = SPI_TIMODE_DISABLE;
  hspi1.Init.CRCCalculation = SPI_CRCCALCULATION_DISABLE;
  hspi1.Init.CRCPolynomial = 10;
  if (HAL_SPI_Init(&hspi1) != HAL_OK)
  {
    Error_Handler();
  }

}

static void MX_USART1_UART_Init(void)
{

  huart1.Instance = USART1;
  huart1.Init.BaudRate = 115200;
  huart1.Init.WordLength = UART_WORDLENGTH_8B;
  huart1.Init.StopBits = UART_STOPBITS_1;
  huart1.Init.Parity = UART_PARITY_NONE;
  huart1.Init.Mode = UART_MODE_TX_RX;
  huart1.Init.HwFlowCtl = UART_HWCONTROL_NONE;
  huart1.Init.OverSampling = UART_OVERSAMPLING_16;
  if (HAL_UART_Init(&huart1) != HAL_OK)
  {
    Error_Handler();
  }

}

static void MX_GPIO_Init(void)
{
  GPIO_InitTypeDef GPIO_InitStruct = {0};

  /* GPIO Ports Clock Enable */
  __HAL_RCC_GPIOC_CLK_ENABLE();
  __HAL_RCC_GPIOH_CLK_ENABLE();
  __HAL_RCC_GPIOA_CLK_ENABLE();
  __HAL_RCC_GPIOB_CLK_ENABLE();

  /*Configure GPIO pin Output Level */
  HAL_GPIO_WritePin(GPIOB, E_CS_Pin|LD2_Pin, GPIO_PIN_RESET);

  /*Configure GPIO pin Output Level */
  HAL_GPIO_WritePin(GPIOC, E_DC_Pin|E_RST_Pin, GPIO_PIN_RESET);

  /*Configure GPIO pin : USER_Btn_Pin */
  GPIO_InitStruct.Pin = USER_Btn_Pin;
  GPIO_InitStruct.Mode = GPIO_MODE_IT_RISING;
  GPIO_InitStruct.Pull = GPIO_NOPULL;
  HAL_GPIO_Init(USER_Btn_GPIO_Port, &GPIO_InitStruct);

  /*Configure GPIO pins : P1_Pin P2_Pin E_BUSY_Pin */
  GPIO_InitStruct.Pin = P1_Pin|P2_Pin|E_BUSY_Pin;
  GPIO_InitStruct.Mode = GPIO_MODE_INPUT;
  GPIO_InitStruct.Pull = GPIO_PULLUP;
  HAL_GPIO_Init(GPIOB, &GPIO_InitStruct);

  /*Configure GPIO pins : E_CS_Pin LD2_Pin */
  GPIO_InitStruct.Pin = E_CS_Pin|LD2_Pin;
  GPIO_InitStruct.Mode = GPIO_MODE_OUTPUT_PP;
  GPIO_InitStruct.Pull = GPIO_NOPULL;
  GPIO_InitStruct.Speed = GPIO_SPEED_FREQ_LOW;
  HAL_GPIO_Init(GPIOB, &GPIO_InitStruct);

  /*Configure GPIO pins : E_DC_Pin E_RST_Pin */
  GPIO_InitStruct.Pin = E_DC_Pin|E_RST_Pin;
  GPIO_InitStruct.Mode = GPIO_MODE_OUTPUT_PP;
  GPIO_InitStruct.Pull = GPIO_NOPULL;
  GPIO_InitStruct.Speed = GPIO_SPEED_FREQ_LOW;
  HAL_GPIO_Init(GPIOC, &GPIO_InitStruct);

  /*Configure GPIO pins : P3_Pin P4_Pin */
  GPIO_InitStruct.Pin = P3_Pin|P4_Pin;
  GPIO_InitStruct.Mode = GPIO_MODE_INPUT;
  GPIO_InitStruct.Pull = GPIO_PULLUP;
  HAL_GPIO_Init(GPIOA, &GPIO_InitStruct);

}

void Error_Handler(void)
{
}

/************************ (C) COPYRIGHT STMicroelectronics *****END OF FILE****/
